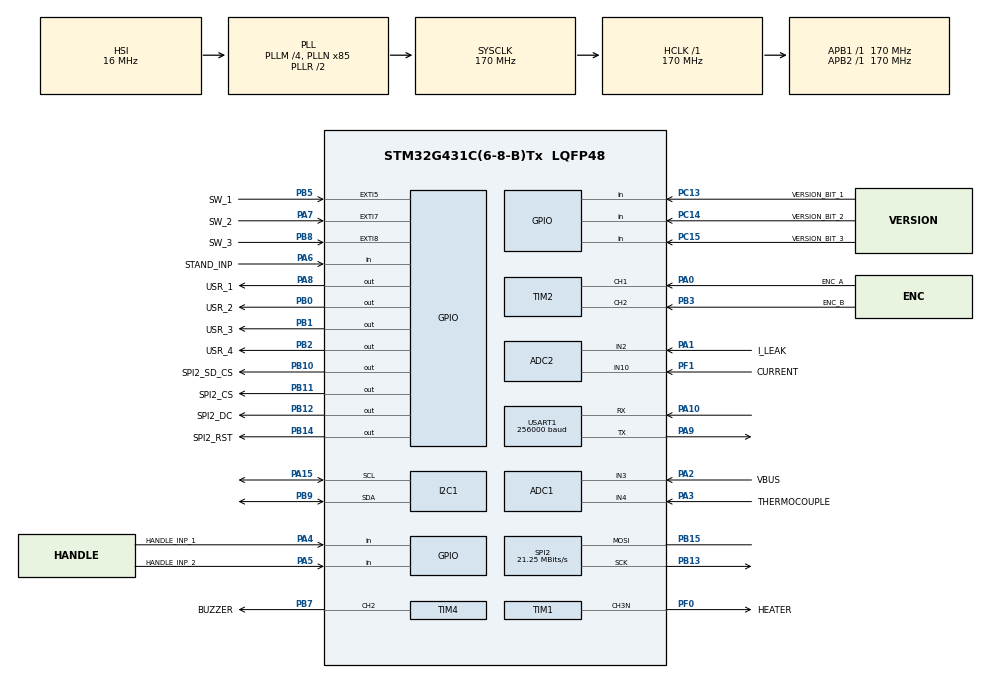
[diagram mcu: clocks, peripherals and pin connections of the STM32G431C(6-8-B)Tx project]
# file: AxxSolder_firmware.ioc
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ADC1.Channel-11\#ChannelRegularConversion=ADC_CHANNEL_3
ADC1.Channel-21\#ChannelRegularConversion=ADC_CHANNEL_4
ADC1.Channel-22\#ChannelRegularConversion=ADC_CHANNEL_TEMPSENSOR_ADC1
ADC1.ClockPrescaler=ADC_CLOCK_ASYNC_DIV4
ADC1.ContinuousConvMode=ENABLE
ADC1.DMAContinuousRequests=ENABLE
ADC1.DiscontinuousConvMode=DISABLE
ADC1.EnableAnalogWatchDog1=false
ADC1.EnableInjectedConversion=DISABLE
ADC1.EnableRegularConversion=ENABLE
ADC1.ExternalTrigConv=ADC_SOFTWARE_START
ADC1.ExternalTrigConvEdge=ADC_EXTERNALTRIGCONVEDGE_NONE
ADC1.NbrOfConversion=3
ADC1.NbrOfConversionFlag=1
ADC1.OffsetNumber-11\#ChannelRegularConversion=ADC_OFFSET_NONE
ADC1.OffsetNumber-21\#ChannelRegularConversion=ADC_OFFSET_NONE
ADC1.OffsetNumber-22\#ChannelRegularConversion=ADC_OFFSET_NONE
ADC1.Overrun=ADC_OVR_DATA_PRESERVED
ADC1.Rank-11\#ChannelRegularConversion=1
ADC1.Rank-21\#ChannelRegularConversion=2
ADC1.Rank-22\#ChannelRegularConversion=3
ADC1.SamplingTime-11\#ChannelRegularConversion=ADC_SAMPLETIME_247CYCLES_5
ADC1.SamplingTime-21\#ChannelRegularConversion=ADC_SAMPLETIME_247CYCLES_5
ADC1.SamplingTime-22\#ChannelRegularConversion=ADC_SAMPLETIME_247CYCLES_5
ADC1.master=1
ADC2.AWD1HighThreshold=2000
ADC2.AWD1ITMode=ENABLE
ADC2.Channel-4\#ChannelRegularConversion=ADC_CHANNEL_2
ADC2.Channel-5\#ChannelRegularConversion=ADC_CHANNEL_10
ADC2.ClockPrescaler=ADC_CLOCK_ASYNC_DIV4
ADC2.ContinuousConvMode=DISABLE
ADC2.DMAContinuousRequests=ENABLE
ADC2.EnableAnalogWatchDog1=true
ADC2.NbrOfConversion=2
ADC2.NbrOfConversionFlag=1
ADC2.OffsetNumber-4\#ChannelRegularConversion=ADC_OFFSET_NONE
ADC2.OffsetNumber-5\#ChannelRegularConversion=ADC_OFFSET_NONE
ADC2.Rank-4\#ChannelRegularConversion=1
ADC2.Rank-5\#ChannelRegularConversion=2
ADC2.SamplingTime-4\#ChannelRegularConversion=ADC_SAMPLETIME_2CYCLES_5
ADC2.SamplingTime-5\#ChannelRegularConversion=ADC_SAMPLETIME_2CYCLES_5
ADC2.WatchdogChannel=ADC_CHANNEL_2
Dma.ADC1.1.Direction=DMA_PERIPH_TO_MEMORY
Dma.ADC1.1.EventEnable=DISABLE
Dma.ADC1.1.Instance=DMA1_Channel3
Dma.ADC1.1.MemDataAlignment=DMA_MDATAALIGN_HALFWORD
Dma.ADC1.1.MemInc=DMA_MINC_ENABLE
Dma.ADC1.1.Mode=DMA_CIRCULAR
Dma.ADC1.1.PeriphDataAlignment=DMA_PDATAALIGN_HALFWORD
Dma.ADC1.1.PeriphInc=DMA_PINC_DISABLE
Dma.ADC1.1.Polarity=HAL_DMAMUX_REQ_GEN_RISING
Dma.ADC1.1.Priority=DMA_PRIORITY_LOW
Dma.ADC1.1.RequestNumber=1
Dma.ADC1.1.SignalID=NONE
Dma.ADC1.1.SyncEnable=DISABLE
Dma.ADC1.1.SyncPolarity=HAL_DMAMUX_SYNC_NO_EVENT
Dma.ADC1.1.SyncRequestNumber=1
Dma.ADC1.1.SyncSignalID=NONE
Dma.ADC2.3.Direction=DMA_PERIPH_TO_MEMORY
Dma.ADC2.3.EventEnable=DISABLE
Dma.ADC2.3.Instance=DMA1_Channel4
Dma.ADC2.3.MemDataAlignment=DMA_MDATAALIGN_HALFWORD
Dma.ADC2.3.MemInc=DMA_MINC_ENABLE
Dma.ADC2.3.Mode=DMA_NORMAL
Dma.ADC2.3.PeriphDataAlignment=DMA_PDATAALIGN_HALFWORD
Dma.ADC2.3.PeriphInc=DMA_PINC_DISABLE
Dma.ADC2.3.Polarity=HAL_DMAMUX_REQ_GEN_RISING
Dma.ADC2.3.Priority=DMA_PRIORITY_LOW
Dma.ADC2.3.RequestNumber=1
Dma.ADC2.3.SignalID=NONE
Dma.ADC2.3.SyncEnable=DISABLE
Dma.ADC2.3.SyncPolarity=HAL_DMAMUX_SYNC_NO_EVENT
Dma.ADC2.3.SyncRequestNumber=1
Dma.ADC2.3.SyncSignalID=NONE
Dma.Request0=SPI2_TX
Dma.Request1=ADC1
Dma.Request2=USART1_TX
Dma.Request3=ADC2
Dma.SPI2_TX.0.Direction=DMA_MEMORY_TO_PERIPH
Dma.SPI2_TX.0.EventEnable=DISABLE
Dma.SPI2_TX.0.Instance=DMA1_Channel1
Dma.SPI2_TX.0.MemDataAlignment=DMA_MDATAALIGN_BYTE
Dma.SPI2_TX.0.MemInc=DMA_MINC_ENABLE
Dma.SPI2_TX.0.Mode=DMA_NORMAL
Dma.SPI2_TX.0.PeriphDataAlignment=DMA_PDATAALIGN_BYTE
Dma.SPI2_TX.0.PeriphInc=DMA_PINC_DISABLE
Dma.SPI2_TX.0.Polarity=HAL_DMAMUX_REQ_GEN_RISING
Dma.SPI2_TX.0.Priority=DMA_PRIORITY_LOW
Dma.SPI2_TX.0.RequestNumber=1
Dma.SPI2_TX.0.SignalID=NONE
Dma.SPI2_TX.0.SyncEnable=DISABLE
Dma.SPI2_TX.0.SyncPolarity=HAL_DMAMUX_SYNC_NO_EVENT
Dma.SPI2_TX.0.SyncRequestNumber=1
Dma.SPI2_TX.0.SyncSignalID=NONE
Dma.USART1_TX.2.Direction=DMA_MEMORY_TO_PERIPH
Dma.USART1_TX.2.EventEnable=DISABLE
Dma.USART1_TX.2.Instance=DMA1_Channel2
Dma.USART1_TX.2.MemDataAlignment=DMA_MDATAALIGN_BYTE
Dma.USART1_TX.2.MemInc=DMA_MINC_ENABLE
Dma.USART1_TX.2.Mode=DMA_NORMAL
Dma.USART1_TX.2.PeriphDataAlignment=DMA_PDATAALIGN_BYTE
Dma.USART1_TX.2.PeriphInc=DMA_PINC_DISABLE
Dma.USART1_TX.2.Polarity=HAL_DMAMUX_REQ_GEN_RISING
Dma.USART1_TX.2.Priority=DMA_PRIORITY_LOW
Dma.USART1_TX.2.RequestNumber=1
Dma.USART1_TX.2.SignalID=NONE
Dma.USART1_TX.2.SyncEnable=DISABLE
Dma.USART1_TX.2.SyncPolarity=HAL_DMAMUX_SYNC_NO_EVENT
Dma.USART1_TX.2.SyncRequestNumber=1
Dma.USART1_TX.2.SyncSignalID=NONE
I2C1.Timing=0x40B285C2
Mcu.Family=STM32G4
Mcu.Name=STM32G431C(6-8-B)Tx
Mcu.Package=LQFP48
NVIC.ADC1_2_IRQn=true\:10\:0\:true\:false\:true\:true\:true\:true
NVIC.DMA1_Channel1_IRQn=true\:0\:0\:true\:false\:true\:false\:true\:true
NVIC.DMA1_Channel2_IRQn=true\:0\:0\:false\:false\:true\:false\:true\:true
NVIC.DMA1_Channel3_IRQn=true\:0\:0\:false\:false\:true\:false\:true\:true
NVIC.DMA1_Channel4_IRQn=true\:0\:0\:false\:false\:true\:false\:true\:true
NVIC.EXTI9_5_IRQn=true\:0\:0\:false\:false\:true\:true\:true\:true
NVIC.PriorityGroup=NVIC_PRIORITYGROUP_4
NVIC.TIM1_BRK_TIM15_IRQn=true\:0\:0\:false\:false\:true\:true\:true\:true
NVIC.TIM1_CC_IRQn=true\:0\:0\:false\:false\:true\:true\:true\:true
NVIC.TIM1_TRG_COM_TIM17_IRQn=true\:0\:0\:false\:false\:true\:true\:true\:true
NVIC.TIM1_UP_TIM16_IRQn=true\:0\:0\:false\:false\:true\:true\:true\:true
NVIC.TIM6_DAC_IRQn=true\:0\:0\:false\:false\:true\:true\:true\:true
NVIC.TIM7_IRQn=true\:0\:0\:false\:false\:true\:true\:true\:true
NVIC.USART1_IRQn=true\:0\:0\:false\:false\:true\:true\:true\:true
PA0.GPIO_Label=ENC_A
PA0.Signal=S_TIM2_CH1
PA1.GPIO_Label=I_LEAK
PA1.Mode=IN2-Single-Ended
PA1.Signal=ADC2_IN2
PA10.Mode=Asynchronous
PA10.Signal=USART1_RX
PA13.Mode=Serial_Wire
PA13.Signal=SYS_JTMS-SWDIO
PA14.Mode=Serial_Wire
PA14.Signal=SYS_JTCK-SWCLK
PA15.Mode=I2C
PA15.Signal=I2C1_SCL
PA2.GPIO_Label=VBUS
PA2.Mode=IN3-Single-Ended
PA2.Signal=ADC1_IN3
PA3.GPIO_Label=THERMOCOUPLE
PA3.Mode=IN4-Single-Ended
PA3.Signal=ADC1_IN4
PA4.GPIO_Label=HANDLE_INP_1
PA4.Signal=GPIO_Input
PA5.GPIO_Label=HANDLE_INP_2
PA5.Signal=GPIO_Input
PA6.GPIO_Label=STAND_INP
PA6.Signal=GPIO_Input
PA7.GPIO_Label=SW_2
PA7.Signal=GPXTI7
PA8.GPIO_Label=USR_1
PA8.Signal=GPIO_Output
PA9.Mode=Asynchronous
PA9.Signal=USART1_TX
PB0.GPIO_Label=USR_2
PB0.Signal=GPIO_Output
PB1.GPIO_Label=USR_3
PB1.Signal=GPIO_Output
PB10.GPIO_Label=SPI2_SD_CS
PB10.Signal=GPIO_Output
PB11.GPIO_Label=SPI2_CS
PB11.Signal=GPIO_Output
PB12.GPIO_Label=SPI2_DC
PB12.Signal=GPIO_Output
PB13.Mode=Simplex_Bidirectional_Master
PB13.Signal=SPI2_SCK
PB14.GPIO_Label=SPI2_RST
PB14.Signal=GPIO_Output
PB15.Mode=Simplex_Bidirectional_Master
PB15.Signal=SPI2_MOSI
PB2.GPIO_Label=USR_4
PB2.Signal=GPIO_Output
PB3.GPIO_Label=ENC_B
PB3.Signal=S_TIM2_CH2
PB5.GPIO_Label=SW_1
PB5.Signal=GPXTI5
PB7.GPIO_Label=BUZZER
PB7.Signal=S_TIM4_CH2
PB8-BOOT0.GPIO_Label=SW_3
PB8-BOOT0.Signal=GPXTI8
PB9.Mode=I2C
PB9.Signal=I2C1_SDA
PC13.GPIO_Label=VERSION_BIT_1
PC13.Signal=GPIO_Input
PC14-OSC32_IN.GPIO_Label=VERSION_BIT_2
PC14-OSC32_IN.Signal=GPIO_Input
PC15-OSC32_OUT.GPIO_Label=VERSION_BIT_3
PC15-OSC32_OUT.Signal=GPIO_Input
PF0-OSC_IN.GPIO_Label=HEATER
PF0-OSC_IN.Mode=PWM Generation3 CH3N
PF0-OSC_IN.Signal=TIM1_CH3N
PF1-OSC_OUT.GPIO_Label=CURRENT
PF1-OSC_OUT.Mode=IN10-Single-Ended
PF1-OSC_OUT.Signal=ADC2_IN10
ProjectManager.HeapSize=0x200
ProjectManager.StackSize=0x400
ProjectManager.TargetToolchain=STM32CubeIDE
RCC.ADC12Freq_Value=170000000
RCC.AHBFreq_Value=170000000
RCC.APB1Freq_Value=170000000
RCC.APB1TimFreq_Value=170000000
RCC.APB2Freq_Value=170000000
RCC.APB2TimFreq_Value=170000000
RCC.CK48CLockSelection=RCC_USBCLKSOURCE_HSI48
RCC.CortexFreq_Value=170000000
RCC.EXTERNAL_CLOCK_VALUE=12288000
RCC.HCLKFreq_Value=170000000
RCC.HSE_VALUE=8000000
RCC.HSI48_VALUE=48000000
RCC.HSI_VALUE=16000000
RCC.LSE_VALUE=32768
RCC.PLLM=RCC_PLLM_DIV4
RCC.PLLN=85
RCC.SYSCLKFreq_VALUE=170000000
RCC.SYSCLKSource=RCC_SYSCLKSOURCE_PLLCLK
RCC.USBFreq_Value=48000000
RCC.VCOOutputFreq_Value=340000000
SH.S_TIM2_CH1.0=TIM2_CH1,Encoder_Interface
SH.S_TIM2_CH2.0=TIM2_CH2,Encoder_Interface
SH.S_TIM4_CH2.0=TIM4_CH2,PWM Generation2 CH2
SPI2.BaudRatePrescaler=SPI_BAUDRATEPRESCALER_8
SPI2.CLKPolarity=SPI_POLARITY_LOW
SPI2.CalculateBaudRate=21.25 MBits/s
SPI2.DataSize=SPI_DATASIZE_8BIT
SPI2.Direction=SPI_DIRECTION_1LINE
SPI2.Mode=SPI_MODE_MASTER
SPI2.VirtualType=VM_MASTER
TIM1.AutoReloadPreload=TIM_AUTORELOAD_PRELOAD_ENABLE
TIM1.Channel-PWM\ Generation1\ No\ Output=TIM_CHANNEL_1
TIM1.Channel-PWM\ Generation3\ CH3N=TIM_CHANNEL_3
TIM1.PeriodNoDither=500
TIM1.Prescaler=17-1
TIM1.TIM_MasterOutputTrigger=TIM_TRGO_RESET
TIM16.AutoReloadPreload=TIM_AUTORELOAD_PRELOAD_ENABLE
TIM16.PeriodNoDither=500-1
TIM16.Prescaler=17000-1
TIM17.AutoReloadPreload=TIM_AUTORELOAD_PRELOAD_ENABLE
TIM17.PeriodNoDither=50-1
TIM17.Prescaler=17000
TIM2.EncoderMode=TIM_ENCODERMODE_TI12
TIM2.IC1Polarity=TIM_ICPOLARITY_FALLING
TIM4.AutoReloadPreload=TIM_AUTORELOAD_PRELOAD_ENABLE
TIM4.Channel-PWM\ Generation2\ CH2=TIM_CHANNEL_2
TIM4.PeriodNoDither=100
TIM4.Prescaler=1700-1
TIM4.PulseNoDither_2=0
TIM6.AutoReloadPreload=TIM_AUTORELOAD_PRELOAD_ENABLE
TIM6.PeriodNoDither=250
TIM6.Prescaler=17000-1
TIM7.AutoReloadPreload=TIM_AUTORELOAD_PRELOAD_ENABLE
TIM7.PeriodNoDither=10-1
TIM7.Prescaler=8500-1
TIM7.TIM_MasterOutputTrigger=TIM_TRGO_UPDATE
USART1.BaudRate=256000
USART1.VirtualMode-Asynchronous=VM_ASYNC
VP_ADC1_TempSens_Input.Mode=IN-TempSens
VP_CRC_VS_CRC.Mode=CRC_Activate
VP_SYS_VS_DBSignals.Mode=DisableDeadBatterySignals
VP_TIM16_VS_ClockSourceINT.Mode=Enable_Timer
VP_TIM17_VS_ClockSourceINT.Mode=Enable_Timer
VP_TIM17_VS_OPM.Mode=OPM_bit
VP_TIM1_VS_no_output1.Mode=PWM Generation1 No Output
VP_TIM6_VS_ClockSourceINT.Mode=Enable_Timer
VP_TIM7_VS_ClockSourceINT.Mode=Enable_Timer
VP_TIM7_VS_OPM.Mode=OPM_bit
VP_TIM8_VS_OPM.Mode=OPM_bit
board=custom

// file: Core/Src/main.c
/* USER CODE BEGIN Header */
/**
  ******************************************************************************
  * @file           : main.c
  * @author  		: Axel Johansson, Stockholm, Sweden
  * @brief          : Main program body of AxxSodler
  ******************************************************************************
  * @attention
  *
  * Copyright (c) 2024 STMicroelectronics.
  * All rights reserved.
  *
  * This software is licensed under terms that can be found in the LICENSE file
  * in the root directory of this software component.
  * If no LICENSE file comes with this software, it is provided AS-IS.
  *
  ******************************************************************************
  */
/* USER CODE END Header */
#include "main.h"

/* USER CODE BEGIN Includes */
#include "lcd.h"
#include "string.h"
#include "pid.h"
#include "moving_average.h"
#include "hysteresis.h"
#include "type_packers.h"
#include "flash.h"
#include "stusb4500.h"
#include "buzzer.h"
#include "debug.h"
#include "menu_settings.h"
#include <math.h>
#include <stdio.h>
#include <float.h>

//#include "usbd_cdc_if.h"
/* USER CODE END Includes */

/* USER CODE BEGIN PTD */
uint8_t fw_version_major =  3;
uint8_t fw_version_minor =  5;
uint8_t fw_version_patch =  2;

//#define PID_TUNING
DEBUG_VERBOSITY_t debugLevel = DEBUG_INFO;

/* Cartridge type specific PID parameters */
#define KP_NT115 					5
#define KI_NT115 					2
#define KD_NT115 					0.3
#define MAX_I_NT115 				300

#define KP_T210 					7
#define KI_T210 					4
#define KD_T210 					0.3
#define MAX_I_T210 					300

#define KP_T245 					8
#define KI_T245 					2
#define KD_T245 					0.5
#define MAX_I_T245 					300

/* General PID parameters */
#define PID_MAX_OUTPUT 500.0f
#define FIXED_MEASURE_DUTY (PID_MAX_OUTPUT / 2)
#define PID_UPDATE_INTERVAL 25
#define PID_ADD_I_MIN_ERROR 75
float PID_NEG_ERROR_I_MULT = 7;
float PID_NEG_ERROR_I_BIAS = 1;

/* Timing constants */
uint32_t previous_millis_display = 0;
uint32_t interval_display = 40;

uint32_t previous_millis_debug = 0;
uint32_t interval_debug = 50;

uint32_t previous_millis_heating_halted_update = 0;
uint32_t interval_heating_halted_update = 500;

uint32_t previous_millis_left_stand = 0;

uint32_t previous_millis_standby = 0;

uint32_t previous_measure_current_update = 0;
uint32_t interval_measure_current = 250;

uint32_t previous_sensor_update_high_update = 0;
uint32_t interval_sensor_update_high_update = 10;

uint32_t previous_sensor_update_low_update = 0;
uint32_t interval_sensor_update_low_update = 100;

uint32_t previous_millis_popup = 0;
uint32_t interval_popup = 2000;

uint32_t previous_stand_debounce = 0;
uint32_t interval_stand_debounce = 100;

cartridge_state_t cartridge_state = ATTACHED;
cartridge_state_t previous_cartridge_state = ATTACHED;

/* power sources */
power_source_t power_source = POWER_DC;

uint8_t sleep_state_written_to_LCD = 0;
uint8_t standby_state_written_to_LCD = 0;

/* Custom tuning parameters */
float Kp_tuning = 0;
float Ki_tuning = 0;
float Kd_tuning = 0;
float temperature_tuning = 100;
float PID_MAX_I_LIMIT_tuning = 0;

/* Allow use of custom temperatue, used for tuning */
uint8_t custom_temperature_on = 0;

/* Buffer for UART print */
char UART_buffer[40];

/* Buffer for UART print */
char DISPLAY_buffer[40];

/* ADC Buffer */
#define ADC1_BUF_LEN 57 //3*19
uint16_t ADC1_BUF[ADC1_BUF_LEN];

/* RAW ADC from current measurement */
uint16_t adc2_dma_buffer[2]; // [0] = channel 2, [1] = channel 10
uint16_t current_raw = 0;
uint16_t current_leak = 0;

/* Stand toggle variables */
uint8_t previous_stand_status = 0;
uint8_t stand_debounced_flag = 0;

/* Thermocouple temperature */
float TC_temp = 0;

/* Flag to indicate that startup sequence is done */
uint8_t startup_done = 0;

/* Flag to indicate that settings menu is active */
uint8_t settings_menu_active = 0;

/* Flag to indicate if beep has been done at set temperature */
uint8_t beeped_at_set_temp = 0;

/* Flag to indicate if a popup is shown */
uint8_t popup_shown = 0;

/* Variables for thermocouple outlier detection */
float TC_temp_from_ADC = 0;
float TC_temp_from_ADC_previous = 0;
float TC_temp_from_ADC_diff = 0;
uint16_t TC_outliers_detected = 0;
#define TC_OUTLIERS_THRESHOLD 300

/* Max allowed tip temperature */
#define EMERGENCY_SHUTDOWN_TEMPERATURE 490

/* Constants for scaling input voltage ADC value*/
#define VOLTAGE_COMPENSATION 0.00840442388
#define CURRENT_COMPENSATION 0.002864

/* Constants for scaling power in W to correct duty cycle */
#define POWER_CONVERSION_FACTOR 0.123

/* Min allowed bus voltage and power */
#define MIN_BUSVOLTAGE 8.0
#define MIN_BUSPOWER 8.0
#define USB_PD_POWER_REDUCTION_FACTOR 1.0

/* Max allowed power per handle type */
#define NT115_MAX_POWER 22
#define T210_MAX_POWER 	65
#define T245_MAX_POWER 	130

/* TC Compensation constants */
#define TC_COMPENSATION_X2_NT115 (5.1026665462522864e-05)
#define TC_COMPENSATION_X1_NT115 0.42050803230712813
#define TC_COMPENSATION_X0_NT115 20.14538589052425

#define TC_COMPENSATION_X2_T210 (4.223931712905644e-06)
#define TC_COMPENSATION_X1_T210 0.31863796444354214
#define TC_COMPENSATION_X0_T210 20.968033870812942

#define TC_COMPENSATION_X2_T245 (-4.735112838956741e-07)
#define TC_COMPENSATION_X1_T245 0.11936452029674384
#define TC_COMPENSATION_X0_T245 23.777399955382318

/* Constants for internal MCU temperture */
#define V30 		0.76 			// from datasheet
#define VSENSE 		(3.3/4096.0) 	// VSENSE value
#define Avg_Slope 	0.0025 			// 2.5mV from datasheet

/* Largest delta temperature before detecting a faulty or missing cartridge */
#define MAX_TC_DELTA_FAULTDETECTION 50

/* Define time for long button press */
#define BTN_LONG_PRESS 15 //*50ms (htim16 interval) --> 15 = 750ms
#define BTN_LONG_LONG_PRESS 40 //*50ms (htim16 interval) --> 40 = 2000ms

/* Button flags */
volatile uint8_t SW_ready = 1;
volatile uint8_t SW_1_pressed = 0;
volatile uint8_t SW_2_pressed = 0;
volatile uint8_t SW_3_pressed = 0;
volatile uint8_t SW_1_pressed_long = 0;
volatile uint8_t SW_1_pressed_long_long = 0;
volatile uint8_t SW_2_pressed_long = 0;
volatile uint8_t SW_3_pressed_long = 0;

/* UART send buffers */
#define MAX_BUFFER_LEN 250
uint8_t UART_transmit_buffer[MAX_BUFFER_LEN];
uint8_t UART_packet_index = 0;
uint8_t UART_packet_length = 0;

///////////////////////////POWER GRAPH
uint8_t draw_pwr_graph=0;

// Display of temperature and power graph

#define background RGB_to_BRG(C_BLACK)
#define color_actual RGB_to_BRG(C_WHITE)

#define GRAPH_X0  34
#define GRAPH_Y0  217
#define GRAPH_WIDTH  250
#define GRAPH_HEIGHT 130

#define TEMP_MIN 0
#define TEMP_MAX 450
#define POWER_MIN 0
#define POWER_MAX 100

#define GRAPH_POINTS 100

#define GRAPH_Color_TEMP    C_FIREBRICK        // Temperature graph color
#define GRAPH_Color_POWER   C_LAWN_GREEN   // Power graph color

#define DASH_LEN_COLOR   C_DARK_GRAY   // Coordinate grid dashed line color
#define DASH_LEN 5                     // Dash length in pixels
#define GAP_LEN  5                     // Gap length in pixels
#define THICKNESS_LEN  1               // Line thickness in pixels

uint16_t temp_array[GRAPH_POINTS];
uint16_t power_array[GRAPH_POINTS];
uint16_t prev_temp_array[GRAPH_POINTS];
uint16_t prev_power_array[GRAPH_POINTS];
uint8_t index_graph = 0;

static uint8_t initialized = 0;

// Structure for storing a line with its color
typedef struct {
    int x1, y1, x2, y2;
    uint16_t color;  // B_RED or B_BLUE or others
} Line;

void add_data_point(uint16_t temp, uint16_t power) {
    temp_array[index_graph] = temp;
    power_array[index_graph] = power;
    index_graph++;
    if (index_graph >= GRAPH_POINTS) index_graph = 0; // Circular buffer
}

static Line temp_lines_prev[GRAPH_POINTS - 1] = {0};
static Line power_lines_prev[GRAPH_POINTS - 1] = {0};

// Universal dashed line using UG_FillFrame()
// dash_len  – dash length in pixels
// gap_len   – gap length in pixels
// thickness – line thickness in pixels
void draw_dashed_line_fillframe(int x1, int y1, int x2, int y2, uint16_t color,
                                uint8_t dash_len, uint8_t gap_len, uint8_t thickness) {
    int dx = abs(x2 - x1), sx = x1 < x2 ? 1 : -1;
    int dy = -abs(y2 - y1), sy = y1 < y2 ? 1 : -1;
    int err = dx + dy, e2;

    uint8_t phase = 0;          // Position inside dash or gap
    uint8_t draw = 1;           // Draw or skip
    uint8_t segment_len = dash_len;

    while (1) {
        if (draw) {
            UG_FillFrame(x1, y1, x1 + (thickness - 1), y1 + (thickness - 1), color);
        }
        phase++;
        if (phase >= segment_len) {
            phase = 0;
            draw = !draw; // Switch drawing mode
            segment_len = draw ? dash_len : gap_len;
        }

        if (x1 == x2 && y1 == y2) break;
        e2 = 2 * err;
        if (e2 >= dy) { err += dy; x1 += sx; }
        if (e2 <= dx) { err += dx; y1 += sy; }
    }
}

void draw_graph_init(void) {
    // Background, grid, and labels are drawn once
    UG_FillFrame(GRAPH_X0, GRAPH_Y0 - GRAPH_HEIGHT , GRAPH_X0 + GRAPH_WIDTH, GRAPH_Y0, background);

    // Draw horizontal dashed lines
    for (int y = 0; y <= GRAPH_HEIGHT; y += GRAPH_HEIGHT / 5) {
        draw_dashed_line_fillframe(GRAPH_X0, GRAPH_Y0 - y, GRAPH_X0 + GRAPH_WIDTH, GRAPH_Y0 - y,
        		DASH_LEN_COLOR, DASH_LEN, GAP_LEN, THICKNESS_LEN); // dash=1, gap=5, thickness=1
    }

    // Draw vertical dashed lines
    for (int x = 0; x <= GRAPH_WIDTH; x += GRAPH_WIDTH / 5) {
        draw_dashed_line_fillframe(GRAPH_X0 + x, GRAPH_Y0 - GRAPH_HEIGHT, GRAPH_X0 + x, GRAPH_Y0,
        		DASH_LEN_COLOR, DASH_LEN, GAP_LEN, THICKNESS_LEN);
    }

    // Labels along the time axis (X, in seconds)
    float step_time_sec = ((float)GRAPH_WIDTH / 5.0f) * ((float)interval_display / 1000.0f);

    for (int i = 0; i <= 5; i++) {
        int x_pos = GRAPH_X0 + i * (GRAPH_WIDTH / 5);
        char buf[12];

        if (i == 0) {
            snprintf(buf, sizeof(buf), "0 s");
        } else {
            // Format time without decimals
            snprintf(buf, sizeof(buf), "%.0f", i * step_time_sec);
        }

        int y_pos = GRAPH_Y0 + 2;

        // For the last label, shift 10 pixels to the left
        int x_draw = (i == 5) ? (x_pos - 15) : x_pos;

        LCD_PutStr(x_draw, y_pos, buf, FONT_arial_19X22, C_PALE_GREEN, background);
    }

    initialized = 1;
}

// Universal function for a line with a given thickness
void draw_line_with_thickness(int x1, int y1, int x2, int y2, uint16_t color, uint8_t thickness) {
    int dx = abs(x2 - x1), sx = x1 < x2 ? 1 : -1;
    int dy = -abs(y2 - y1), sy = y1 < y2 ? 1 : -1;
    int err = dx + dy, e2;

    while (1) {
        // Thickness in pixels (square brush)
        UG_FillFrame(x1, y1, x1 + (thickness - 1), y1 + (thickness - 1), color);

        if (x1 == x2 && y1 == y2) break;
        e2 = 2 * err;
        if (e2 >= dy) { err += dy; x1 += sx; }
        if (e2 <= dx) { err += dx; y1 += sy; }
    }
}

// Restore grid dash
void restore_grid_point(int x, int y) {
    // Horizontal grid lines
    for (int gy = 0; gy <= GRAPH_HEIGHT; gy += GRAPH_HEIGHT / 5) {
        int grid_y = GRAPH_Y0 - gy;
        if (abs(y - grid_y) <= THICKNESS_LEN) {
            int cycle_len = DASH_LEN + GAP_LEN;
            int dash_index = (x - GRAPH_X0) / cycle_len;
            int dash_start = GRAPH_X0 + dash_index * cycle_len;
            int dash_end = dash_start + DASH_LEN - 1;

            if (dash_end > GRAPH_X0 + GRAPH_WIDTH) dash_end = GRAPH_X0 + GRAPH_WIDTH;

            // Draw the whole dash
            UG_FillFrame(dash_start, grid_y,
                         dash_end,   grid_y,
						 DASH_LEN_COLOR);
            return;
        }
    }

    // Vertical grid lines
    for (int gx = 0; gx <= GRAPH_WIDTH; gx += GRAPH_WIDTH / 5) {
        int grid_x = GRAPH_X0 + gx;
        if (abs(x - grid_x) <= THICKNESS_LEN) {
            int cycle_len = DASH_LEN + GAP_LEN;
            int dash_index = (GRAPH_Y0 - y) / cycle_len;
            int dash_start = GRAPH_Y0 - dash_index * cycle_len;
            int dash_end = dash_start - (DASH_LEN - 1);

            if (dash_end < GRAPH_Y0 - GRAPH_HEIGHT) dash_end = GRAPH_Y0 - GRAPH_HEIGHT;

            UG_FillFrame(grid_x,
                         dash_end, grid_x,
                         dash_start,
						 DASH_LEN_COLOR);
            return;
        }
    }
}

// Erases a line 2 pixels thick and restores the grid
void erase_line_and_restore_grid(int x1, int y1, int x2, int y2) {
    // Erase with thickness of 2 pixels
    draw_line_with_thickness(x1, y1, x2, y2, background, 2);

    int dx = abs(x2 - x1);
    int dy = abs(y2 - y1);

    int sx = (x1 < x2) ? 1 : -1;
    int sy = (y1 < y2) ? 1 : -1;

    int err = dx - dy;

    while (1) {
        restore_grid_point(x1, y1);

        if (x1 == x2 && y1 == y2)
            break;

        int e2 = err * 2;
        if (e2 > -dy) {
            err -= dy;
            x1 += sx;
        }
        if (e2 < dx) {
            err += dx;
            y1 += sy;
        }
    }
}

// Check if two line segments overlap within rectangles, with margin (thickness)
bool lines_overlap(Line *l1, Line *l2, int thickness) {
    int l1_xmin = l1->x1 < l1->x2 ? l1->x1 : l1->x2;
    int l1_xmax = l1->x1 > l1->x2 ? l1->x1 : l1->x2;
    int l1_ymin = l1->y1 < l1->y2 ? l1->y1 : l1->y2;
    int l1_ymax = l1->y1 > l1->y2 ? l1->y1 : l1->y2;

    int l2_xmin = l2->x1 < l2->x2 ? l2->x1 : l2->x2;
    int l2_xmax = l2->x1 > l2->x2 ? l2->x1 : l2->x2;
    int l2_ymin = l2->y1 < l2->y2 ? l2->y1 : l2->y2;
    int l2_ymax = l2->y1 > l2->y2 ? l2->y1 : l2->y2;

    // Add thickness margin for "overlap"
    l1_xmin -= thickness;
    l1_xmax += thickness;
    l1_ymin -= thickness;
    l1_ymax += thickness;

    l2_xmin -= thickness;
    l2_xmax += thickness;
    l2_ymin -= thickness;
    l2_ymax += thickness;

    bool x_overlap = (l1_xmin <= l2_xmax) && (l1_xmax >= l2_xmin);
    bool y_overlap = (l1_ymin <= l2_ymax) && (l1_ymax >= l2_ymin);

    return x_overlap && y_overlap;
}

// Helper function for drawing an axis with labels
// values      - array of values for labels
// count       - number of labels in the array
// x           - horizontal position for label output
// is_left_axis - true if the axis is on the left (labels on the left), false if on the right
// unit_start  - suffix for the first label (e.g., "°C" or "%"), can be NULL
// unit_end    - suffix for the last label, can be NULL
void draw_axis(const int *values, int count, int x, bool is_left_axis,
               uint16_t color, const char *unit_start, const char *unit_end) {
    // Upper and lower Y boundaries so labels don't go outside the grid
    int y_min = GRAPH_Y0 - GRAPH_HEIGHT + 10; // slightly below the top grid line
    int y_max = GRAPH_Y0 - 5;                 // slightly above the bottom grid line

    for (int i = 0; i < count; i++) {
        int y_pos;

        if (i == 0) {
            y_pos = y_max;  // Bottom label (minimum value)
        } else if (i == count - 1) {
            y_pos = y_min;  // Top label (maximum value)
        } else {
            // Evenly distribute remaining labels between top and bottom boundaries
            float fraction = (float)i / (count - 1);
            y_pos = y_max - (int)((y_max - y_min) * fraction);
        }

        char buf[12];

        // Form a string with units only for the first label, others without units
        if (i == 0 && unit_start) {
            snprintf(buf, sizeof(buf), "%d%s", values[i], unit_start);
        } else {
            snprintf(buf, sizeof(buf), "%d", values[i]);
        }

        // For the left axis, use a fixed offset from the left (2 pixels)
        int x_pos = x;
        if (is_left_axis) {
            x_pos = 2;
        }

        // Output label on the screen with vertical offset -15 for visual alignment
        LCD_PutStr(x_pos, y_pos - 15, buf, FONT_arial_19X22, color, background);
    }
}

// Change graph axis label colors depending on sensor_values.current_state
void draw_axis_labels(void) {
    // Select label colors once depending on the state
    uint16_t color_temp_label = (sensor_values.current_state == RUN) ? color_actual : GRAPH_Color_TEMP;
    uint16_t color_power_label = (sensor_values.current_state == RUN) ? GRAPH_Color_POWER : C_BLUE;

    // Arrays of values for the temperature axis and the power axis
    int temp_values[] = {0, 90, 180, 270, 360, 450};
    int power_values[] = {0, 20, 40, 60, 80, 100};

    // Draw the left temperature axis (with "°C" symbol at the minimum value)
    draw_axis(temp_values, sizeof(temp_values)/sizeof(temp_values[0]), 2, true, color_temp_label, "°C", NULL);

    // Draw the right power axis (with % at the minimum value)
    draw_axis(power_values, sizeof(power_values)/sizeof(power_values[0]), GRAPH_X0 + GRAPH_WIDTH + 3, false, color_power_label, "%", "");
}

void check_and_update_labels(void) {
	uint8_t last_sensor_state = 0xFF;
	if (last_sensor_state != sensor_values.current_state) {
        draw_axis_labels();
        last_sensor_state = sensor_values.current_state;
    }
}

void draw_graph_update(void) {
    if (!initialized) {
        draw_graph_init();
    }

    check_and_update_labels();

    // Update temperature and power lines with partial erasing
    for (uint8_t i = 1; i < GRAPH_POINTS; i++) {
        uint8_t idx_prev = (index_graph + i - 1) % GRAPH_POINTS;
        uint8_t idx_curr = (index_graph + i) % GRAPH_POINTS;

        // Temperature points
        int x_prev_temp = GRAPH_X0 + ((i - 1) * GRAPH_WIDTH) / (GRAPH_POINTS - 1);
        int x_curr_temp = GRAPH_X0 + (i * GRAPH_WIDTH) / (GRAPH_POINTS - 1);
        int y_prev_temp = GRAPH_Y0 - ((temp_array[idx_prev] - TEMP_MIN) * GRAPH_HEIGHT) / (TEMP_MAX - TEMP_MIN);
        int y_curr_temp = GRAPH_Y0 - ((temp_array[idx_curr] - TEMP_MIN) * GRAPH_HEIGHT) / (TEMP_MAX - TEMP_MIN);

        uint16_t color_temp = (sensor_values.current_state == RUN) ? color_actual : GRAPH_Color_TEMP;

        Line new_temp_line = {x_prev_temp, y_prev_temp, x_curr_temp, y_curr_temp, color_temp};
        Line *old_temp_line = &temp_lines_prev[i - 1];

        // Power lines (offset +2 pixels)
        int x_prev_power = x_prev_temp;
        int x_curr_power = x_curr_temp;
        int y_prev_power = (GRAPH_Y0 - ((power_array[idx_prev] - POWER_MIN) * GRAPH_HEIGHT) / (POWER_MAX - POWER_MIN));
        int y_curr_power = (GRAPH_Y0 - ((power_array[idx_curr] - POWER_MIN) * GRAPH_HEIGHT) / (POWER_MAX - POWER_MIN));

        uint16_t color_power = (sensor_values.current_state == RUN) ? GRAPH_Color_POWER : C_BLUE;

        Line new_power_line = {x_prev_power, y_prev_power, x_curr_power, y_curr_power, color_power};
        Line *old_power_line = &power_lines_prev[i - 1];

        bool temp_line_changed = (old_temp_line->x1 != new_temp_line.x1) || (old_temp_line->y1 != new_temp_line.y1) ||
                                 (old_temp_line->x2 != new_temp_line.x2) || (old_temp_line->y2 != new_temp_line.y2) ||
                                 (old_temp_line->color != new_temp_line.color);

        bool power_line_changed = (old_power_line->x1 != new_power_line.x1) || (old_power_line->y1 != new_power_line.y1) ||
                                  (old_power_line->x2 != new_power_line.x2) || (old_power_line->y2 != new_power_line.y2) ||
                                  (old_power_line->color != new_power_line.color);

        // Check intersection of old lines if at least one line has changed
        if (temp_line_changed || power_line_changed) {
            bool overlap = false;

            if ((old_temp_line->x1 || old_temp_line->y1 || old_temp_line->x2 || old_temp_line->y2) &&
                (old_power_line->x1 || old_power_line->y1 || old_power_line->x2 || old_power_line->y2)) {
                overlap = lines_overlap(old_temp_line, old_power_line, 2);
            }

            if (overlap) {
                // Erase both lines and restore the grid
                erase_line_and_restore_grid(old_temp_line->x1, old_temp_line->y1, old_temp_line->x2, old_temp_line->y2);
                erase_line_and_restore_grid(old_power_line->x1, old_power_line->y1, old_power_line->x2, old_power_line->y2);
            } else {
                // Erase only changed lines individually
                if (temp_line_changed && (old_temp_line->x1 || old_temp_line->y1 || old_temp_line->x2 || old_temp_line->y2)) {
                    erase_line_and_restore_grid(old_temp_line->x1, old_temp_line->y1, old_temp_line->x2, old_temp_line->y2);
                }
                if (power_line_changed && (old_power_line->x1 || old_power_line->y1 || old_power_line->x2 || old_power_line->y2)) {
                    erase_line_and_restore_grid(old_power_line->x1, old_power_line->y1, old_power_line->x2, old_power_line->y2);
                }
            }
        }

        // Draw new lines
        draw_line_with_thickness(new_temp_line.x1, new_temp_line.y1, new_temp_line.x2, new_temp_line.y2, new_temp_line.color, 2);
        draw_line_with_thickness(new_power_line.x1, new_power_line.y1, new_power_line.x2, new_power_line.y2, new_power_line.color, 2);

        // Save new lines to prev
        temp_lines_prev[i - 1] = new_temp_line;
        power_lines_prev[i - 1] = new_power_line;
    }
}

///////////////////////////

enum handles attached_handle;

/* Struct to hold sensor values */
struct sensor_values_struct {
	float set_temperature;
	float thermocouple_temperature;
	float thermocouple_temperature_previous;
	float thermocouple_temperature_filtered;
	float requested_power;
	float requested_power_filtered;
	float bus_voltage;
	float heater_current;
	uint16_t leak_current;
	float mcu_temperature;
	float in_stand;
	float handle1_sense;
	float handle2_sense;
	mainstates current_state;
	mainstates previous_state;
	float max_power_watt;
	float USB_PD_power_limit;
};

/* Struct to hold sensor values */
sensor_values_struct sensor_values = {
    .set_temperature = 0.0f,
    .thermocouple_temperature = 0.0f,
    .thermocouple_temperature_previous = 0.0f,
    .thermocouple_temperature_filtered = 0.0f,
    .requested_power = 0.0f,
    .requested_power_filtered = 0.0f,
    .bus_voltage = 0.0f,
    .heater_current = 0.0f,
    .leak_current = 0,
    .mcu_temperature = 0.0f,
    .in_stand = 0.0f,
    .handle1_sense = 0.0f,
    .handle2_sense = 0.0f,
    .current_state = SLEEP,
    .previous_state = SLEEP,
    .max_power_watt = 0.0f,
    .USB_PD_power_limit = DBL_MAX
};

/* Struct to hold flash values */
Flash_values flash_values;
Flash_values default_flash_values = {.startup_temperature = 330,
									.temperature_offset = 0,
									.standby_temp = 150,
									.standby_time = 10,
									.emergency_time = 30,
									.buzzer_enabled = 1,
									.preset_temp_1 = 330,
									.preset_temp_2 = 430,
									.GPIO4_ON_at_run = 0,
									.screen_rotation = 0,
									.power_limit = 0,
									.current_measurement = 1,
									.startup_beep = 1,
									.deg_celsius = 1,
									.temp_cal_100 = 100,
									.temp_cal_200 = 200,
									.temp_cal_300 = 300,
									.temp_cal_350 = 350,
									.temp_cal_400 = 400,
									.temp_cal_450 = 450,
									.serial_debug_print = 0,
									.displayed_temp_filter = 5,
									.startup_temp_is_previous_temp = 0,
									.three_button_mode = 0,
									.beep_at_set_temp = 1,
									.beep_tone = 0,
									.momentary_stand = 0,
									.power_unit = 0,
									.detect_nt115 = 0};

/* PID data */
float PID_setpoint = 0.0f;

/* Flags for temp and current measurements */
volatile uint8_t current_measurement_requested = 0;
uint8_t current_measurement_done = 1;
uint8_t thermocouple_measurement_requested = 0;
uint8_t thermocouple_measurement_done = 1;

/* Moving average filters for sensor data */
FilterTypeDef thermocouple_temperature_filter_struct;
FilterTypeDef thermocouple_temperature_filtered_filter_struct;
FilterTypeDef requested_power_filtered_filter_struct;
FilterTypeDef mcu_temperature_filter_struct;
FilterTypeDef input_voltage_filterStruct;
FilterTypeDef current_filterStruct;
FilterTypeDef stand_sense_filterStruct;
FilterTypeDef handle1_sense_filterStruct;
FilterTypeDef handle2_sense_filterStruct;

/* Hysteresis filters for sensor data */
Hysteresis_FilterTypeDef thermocouple_temperature_filtered_hysteresis;

/* USER CODE END PTD */

ADC_HandleTypeDef hadc1;
ADC_HandleTypeDef hadc2;
DMA_HandleTypeDef hdma_adc1;
DMA_HandleTypeDef hdma_adc2;

CRC_HandleTypeDef hcrc;

I2C_HandleTypeDef hi2c1;

SPI_HandleTypeDef hspi2;
DMA_HandleTypeDef hdma_spi2_tx;

TIM_HandleTypeDef htim1;
TIM_HandleTypeDef htim2;
TIM_HandleTypeDef htim4;
TIM_HandleTypeDef htim6;
TIM_HandleTypeDef htim7;
TIM_HandleTypeDef htim8;
TIM_HandleTypeDef htim16;
TIM_HandleTypeDef htim17;

UART_HandleTypeDef huart1;
DMA_HandleTypeDef hdma_usart1_tx;

void SystemClock_Config(void);
static void MX_GPIO_Init(void);
static void MX_DMA_Init(void);
static void MX_ADC1_Init(void);
static void MX_ADC2_Init(void);
static void MX_CRC_Init(void);
static void MX_TIM1_Init(void);
static void MX_TIM2_Init(void);
static void MX_TIM4_Init(void);
static void MX_SPI2_Init(void);
static void MX_I2C1_Init(void);
static void MX_USART1_UART_Init(void);
static void MX_TIM7_Init(void);
static void MX_TIM8_Init(void);
static void MX_TIM6_Init(void);
static void MX_TIM16_Init(void);
static void MX_TIM17_Init(void);

/* USER CODE BEGIN 0 */
PID_TypeDef TPID;

/* Function to clamp d between the limits min and max */
float clamp(float d, float min, float max) {
    if (d < min) return min;
    if (d > max) return max;
    return d;
}

/* Function to get min value of a and b */
float min(float a, float b) {
  return a < b ? a : b;
}

/**
 * @brief Returns the average value of 100 readings at index + 3*n in the ADC_buffer vector.
 * It is assumed that ADC1_BUF contains data from 3 channels, collected sequentially.
 * For example, if index == 0, elements 0, 3, 6, ... are used;
 * if index == 1, then 1, 4, 7, ... and so on.
 * @param index Channel index (0, 1, or 2)
 * @return Average value for that channel
 */
float get_mean_ADC_reading_indexed(uint8_t index){
	if (index > 2) return 0.0f;  // Incorrect Index Protection

    float ADC_filter_mean = 0.0f;
    int count = 0;

    for (int n = index; n < ADC1_BUF_LEN; n += 3) {
        ADC_filter_mean += ADC1_BUF[n];
        count++;
    }

    return (count > 0) ? (ADC_filter_mean / (float)count) : 0.0f;
}

/**
 * @brief Retrieves the hardware version of the device based on the state of 3 input pins.
 * The states of the VERSION_BIT_1..3 pins form a 3-bit number:
 *     VERSION_BIT_3 - most significant bit (MSB)
 *     VERSION_BIT_2 - middle bit
 *     VERSION_BIT_1 - least significant bit (LSB)
 *
 * Version numbering starts from 3, i.e., version = 3 + [bit value]
 *
 * @return uint8_t Hardware version number (3..10)
 */
uint8_t get_hw_version(){
    uint8_t version_bits =
        (HAL_GPIO_ReadPin(GPIOC, VERSION_BIT_3_Pin) << 2) |
        (HAL_GPIO_ReadPin(GPIOC, VERSION_BIT_2_Pin) << 1) |
        (HAL_GPIO_ReadPin(GPIOC, VERSION_BIT_1_Pin) << 0);

    return 3 + version_bits;
}

/* Convert RGB colour to BRG color */
uint16_t RGB_to_BRG(uint16_t color){
	return ((((color & 0b0000000000011111)  << 11) & 0b1111100000000000) | ((color & 0b1111111111100000) >> 5));
}

/* Function to change the main state */
void change_state(mainstates new_state){
    // Save the previous state
	sensor_values.previous_state = sensor_values.current_state;
	// Set the new current state
	sensor_values.current_state = new_state;
    // If transitioning TO RUN STATE and the current temperature should be saved as the startup temperature
	if((sensor_values.previous_state != RUN) && (sensor_values.current_state == RUN) && (flash_values.startup_temp_is_previous_temp == 1)){
		flash_values.startup_temperature = sensor_values.set_temperature;
		FlashWrite(&flash_values);
	}
	// Enable GPIO4 when transitioning to RUN, if the corresponding setting is active
	if((sensor_values.current_state == RUN) && (flash_values.GPIO4_ON_at_run == 1)){
		HAL_GPIO_WritePin(GPIOB, USR_4_Pin, GPIO_PIN_SET); // Set the USR_4 output to high level
	}
	else{
		HAL_GPIO_WritePin(GPIOB, USR_4_Pin, GPIO_PIN_RESET); // Set the USR_4 output to low level
	}
    // Reset the beep flag upon reaching the temperature — only when entering RUN
    if((sensor_values.previous_state != RUN) && (sensor_values.current_state == RUN)){
            beeped_at_set_temp = 0;
    }
}

/* Function to get the filtered MCU temperature */
void get_mcu_temp(){
	sensor_values.mcu_temperature =	Moving_Average_Compute((((get_mean_ADC_reading_indexed(2) * VSENSE) - V30) / Avg_Slope + 25), &mcu_temperature_filter_struct); //Index 2 is MCU temp
}

/* Function to get the filtered bus voltage */
void get_bus_voltage(){
	sensor_values.bus_voltage = Moving_Average_Compute(get_mean_ADC_reading_indexed(0), &input_voltage_filterStruct)*VOLTAGE_COMPENSATION; //Index 0 is bus voltage
}

/* Function to get the filtered heater current */
void get_heater_current(){
	sensor_values.heater_current = Moving_Average_Compute(current_raw, &current_filterStruct)*CURRENT_COMPENSATION;
}

void get_thermocouple_temperature(){
	/* --- Step 1: Outlier filter on raw ADC data --- */
	TC_temp_from_ADC_previous = TC_temp_from_ADC;
	TC_temp_from_ADC = get_mean_ADC_reading_indexed(1);
	TC_temp_from_ADC_diff = fabs(TC_temp_from_ADC_previous - TC_temp_from_ADC);

	if((TC_temp_from_ADC_diff > TC_OUTLIERS_THRESHOLD) && (TC_outliers_detected < 2)){
		TC_outliers_detected++;
		if(TC_outliers_detected < 2){
			TC_temp_from_ADC = TC_temp_from_ADC_previous;
		}
	}
	else{
		TC_outliers_detected = 0;
	}

	/* --- Step 2: Moving average filter --- */
	TC_temp = Moving_Average_Compute(TC_temp_from_ADC, &thermocouple_temperature_filter_struct); /* Moving average */

	/* --- Step 3: Apply handle-specific compensation polynomial --- */
	if(attached_handle == T210){
		sensor_values.thermocouple_temperature = TC_temp*TC_temp*TC_COMPENSATION_X2_T210 + TC_temp*TC_COMPENSATION_X1_T210 + TC_COMPENSATION_X0_T210;
	}
	else if(attached_handle == T245){
		sensor_values.thermocouple_temperature = TC_temp*TC_temp*TC_COMPENSATION_X2_T245 + TC_temp*TC_COMPENSATION_X1_T245 + TC_COMPENSATION_X0_T245;
	}
	else if(attached_handle == NT115){
		sensor_values.thermocouple_temperature = TC_temp*TC_temp*TC_COMPENSATION_X2_NT115 + TC_temp*TC_COMPENSATION_X1_NT115 + TC_COMPENSATION_X0_NT115;
	}

	/* --- Step 4: Adjust measured temperature to fit calibrated values */
	if(sensor_values.thermocouple_temperature < 100){
		sensor_values.thermocouple_temperature = sensor_values.thermocouple_temperature*(flash_values.temp_cal_100)/100.0f;
		}
	else if(sensor_values.thermocouple_temperature < 200){
		sensor_values.thermocouple_temperature = (sensor_values.thermocouple_temperature - 100.0f)*(flash_values.temp_cal_200-flash_values.temp_cal_100)/100.0f + flash_values.temp_cal_100;
		}
	else if(sensor_values.thermocouple_temperature < 300){
		sensor_values.thermocouple_temperature = (sensor_values.thermocouple_temperature - 200.0f)*(flash_values.temp_cal_300-flash_values.temp_cal_200)/100.0f + flash_values.temp_cal_200;
	}
	else if(sensor_values.thermocouple_temperature < 350){
		sensor_values.thermocouple_temperature = (sensor_values.thermocouple_temperature - 300.0f)*(flash_values.temp_cal_350-flash_values.temp_cal_300)/50.0f + flash_values.temp_cal_300;
		}
	else if(sensor_values.thermocouple_temperature < 400){
		sensor_values.thermocouple_temperature = (sensor_values.thermocouple_temperature - 350.0f)*(flash_values.temp_cal_400-flash_values.temp_cal_350)/50.0f + flash_values.temp_cal_350;
		}
	else{
		sensor_values.thermocouple_temperature = (sensor_values.thermocouple_temperature - 400.0f)*(flash_values.temp_cal_450-flash_values.temp_cal_400)/50.0f + flash_values.temp_cal_400;
		}
	// Add temperature offset value
	sensor_values.thermocouple_temperature += flash_values.temperature_offset;
	// Clamp
	sensor_values.thermocouple_temperature = clamp(sensor_values.thermocouple_temperature ,0 ,500);

	sensor_values.thermocouple_temperature_filtered = Moving_Average_Compute(sensor_values.thermocouple_temperature, &thermocouple_temperature_filtered_filter_struct); // Moving average filter
	sensor_values.thermocouple_temperature_filtered = Hysteresis_Add(sensor_values.thermocouple_temperature_filtered, &thermocouple_temperature_filtered_hysteresis); // Hysteresis filter
}

/* Sets the duty cycle of timer controlling the heater */
void set_heater_duty(uint16_t dutycycle){
	__HAL_TIM_SET_COMPARE(&htim1, TIM_CHANNEL_3, dutycycle);
	__HAL_TIM_SET_COMPARE(&htim1, TIM_CHANNEL_1, (uint16_t)(dutycycle * 0.3f));
}

/* Update the duty cycle of timer controlling the heater PWM */
void update_heater_PWM(){
	if (sensor_values.bus_voltage <= 0.0f) return;

    float current = (sensor_values.max_power_watt * POWER_CONVERSION_FACTOR) / sensor_values.bus_voltage;
    float duty_cycle = sensor_values.requested_power * current;

    duty_cycle = clamp(duty_cycle, 0.0f, PID_MAX_OUTPUT);
    set_heater_duty(duty_cycle);
}

/* Disable the duty cycle of timer controlling the heater PWM*/
void heater_off(){
	set_heater_duty(0);
}

/* Return the temperature in the correct unit */
float convert_temperature(float temperature){
	if (flash_values.deg_celsius == 1){
		return temperature;
	}
	else{
		return ((temperature * 9) + 3) / 5 + 32;
	}
}

/* Formatting float into a string as right-aligned, by adding spaces on the left */
void format_number_right(float input, char* buffer) {
    int rounded = (int)roundf(input);
    clamp(rounded, 0, 999);

    char number_str[4]; // Enough for "100" + '\0'
    sprintf(number_str, "%d", rounded);

    int num_digits = strlen(number_str);
    int padding_spaces = (3 - num_digits) * 2;

    // Fill padding spaces first
    memset(buffer, ' ', padding_spaces);
    // Copy the number after the padding
    strcpy(buffer + padding_spaces, number_str);

    // Null terminate the full string
    buffer[padding_spaces + num_digits] = '\0';
}

/* Formatting float into a string as left-aligned, by adding spaces on the right */
void format_number_left(float input, char* buffer) {
    int rounded = (int)roundf(input);
    clamp(rounded, 0, 999);

    char number_str[4]; // "100" + '\0'
    sprintf(number_str, "%d", rounded);

    int num_digits = strlen(number_str);
    int padding_spaces = (3 - num_digits) * 2;

    // Copy number into buffer
    strcpy(buffer, number_str);

    // Add spaces to the right
    memset(buffer + num_digits, ' ', padding_spaces);
    buffer[num_digits + padding_spaces] = '\0';
}

void update_display(){
	float filtered_power_percent = sensor_values.requested_power_filtered/PID_MAX_OUTPUT;
	float filtered_power_watt = sensor_values.max_power_watt*filtered_power_percent;

	if((flash_values.screen_rotation == 0) || (flash_values.screen_rotation == 2)){
		memset(&DISPLAY_buffer, '\0', sizeof(DISPLAY_buffer));
		format_number_left(convert_temperature(sensor_values.set_temperature), DISPLAY_buffer);
		LCD_PutStr(19, 70, DISPLAY_buffer, FONT_arial_36X44_NUMBERS, RGB_to_BRG(C_WHITE), RGB_to_BRG(C_BLACK));

		if(cartridge_state == DETACHED) {
			LCD_PutStr(15, 160, " ---  ", FONT_arial_36X44_NUMBERS, RGB_to_BRG(C_WHITE), RGB_to_BRG(C_BLACK));
		}
		else{
			memset(&DISPLAY_buffer, '\0', sizeof(DISPLAY_buffer));
			format_number_left(convert_temperature(sensor_values.thermocouple_temperature_filtered), DISPLAY_buffer);
			LCD_PutStr(19, 160, DISPLAY_buffer, FONT_arial_36X44_NUMBERS, RGB_to_BRG(C_WHITE), RGB_to_BRG(C_BLACK));
		}

		memset(&DISPLAY_buffer, '\0', sizeof(DISPLAY_buffer));
		sprintf(DISPLAY_buffer, "%.1f", sensor_values.bus_voltage);
		LCD_PutStr(125, 255, DISPLAY_buffer, FONT_arial_17X18, RGB_to_BRG(C_WHITE), RGB_to_BRG(C_BLACK));

		memset(&DISPLAY_buffer, '\0', sizeof(DISPLAY_buffer));
		if(convert_temperature(sensor_values.mcu_temperature) < 99.5){
			sprintf(DISPLAY_buffer, "%.0f", convert_temperature(sensor_values.mcu_temperature));
		}
		else{
			sprintf(DISPLAY_buffer, "%.0f", convert_temperature(sensor_values.mcu_temperature));
		}
		LCD_PutStr(59, 275, DISPLAY_buffer, FONT_arial_17X18, RGB_to_BRG(C_WHITE), RGB_to_BRG(C_BLACK));

		if(attached_handle == T210){
			LCD_PutStr(125, 235, "T210   ", FONT_arial_17X18, RGB_to_BRG(C_WHITE), RGB_to_BRG(C_BLACK));
		}
		else if(attached_handle == T245){
			LCD_PutStr(125, 235, "T245   ", FONT_arial_17X18, RGB_to_BRG(C_WHITE), RGB_to_BRG(C_BLACK));
		}
		else if(attached_handle == NT115){
			LCD_PutStr(125, 235, "NT115", FONT_arial_17X18, RGB_to_BRG(C_WHITE), RGB_to_BRG(C_BLACK));
		}

		if(sensor_values.max_power_watt < 100){
			sprintf(DISPLAY_buffer, "  %.0f W", sensor_values.max_power_watt);
		}
		else{
			sprintf(DISPLAY_buffer, "%.0f W", sensor_values.max_power_watt);
		}
		LCD_PutStr(185, 45, DISPLAY_buffer, FONT_arial_17X18, RGB_to_BRG(C_WHITE), RGB_to_BRG(C_BLACK));

		memset(&DISPLAY_buffer, '\0', sizeof(DISPLAY_buffer));
		if(flash_values.power_unit == 0){
					format_number_right(filtered_power_watt, DISPLAY_buffer);
				}
				else{
					format_number_right(100*filtered_power_percent, DISPLAY_buffer);
				};
		LCD_PutStr(190, 275, DISPLAY_buffer, FONT_arial_17X18, RGB_to_BRG(C_WHITE), RGB_to_BRG(C_BLACK));

		if((sensor_values.current_state == SLEEP || sensor_values.current_state == EMERGENCY_SLEEP || sensor_values.current_state == HALTED) && !sleep_state_written_to_LCD){
			UG_FillFrame(210,66,230,268, RGB_to_BRG(C_ORANGE));
			LCD_PutStr(214, 73,  " ", FONT_arial_20X23, RGB_to_BRG(C_BLACK), RGB_to_BRG(C_ORANGE));
			LCD_PutStr(216, 99,  "S", FONT_arial_20X23, RGB_to_BRG(C_BLACK), RGB_to_BRG(C_ORANGE));
			LCD_PutStr(214, 129, "L", FONT_arial_20X23, RGB_to_BRG(C_BLACK), RGB_to_BRG(C_ORANGE));
			LCD_PutStr(216, 158, "E", FONT_arial_20X23, RGB_to_BRG(C_BLACK), RGB_to_BRG(C_ORANGE));
			LCD_PutStr(214, 191, "E", FONT_arial_20X23, RGB_to_BRG(C_BLACK), RGB_to_BRG(C_ORANGE));
			LCD_PutStr(216, 217, "P", FONT_arial_20X23, RGB_to_BRG(C_BLACK), RGB_to_BRG(C_ORANGE));
			LCD_PutStr(214, 247, " ", FONT_arial_20X23, RGB_to_BRG(C_BLACK), RGB_to_BRG(C_ORANGE));
			sleep_state_written_to_LCD = 1;
			standby_state_written_to_LCD = 0;
		}
		else if((sensor_values.current_state == STANDBY) && !standby_state_written_to_LCD){
			UG_FillFrame(210,66,230,268, RGB_to_BRG(C_ORANGE));
			LCD_PutStr(213, 73,  "S", FONT_arial_20X23, RGB_to_BRG(C_BLACK), RGB_to_BRG(C_ORANGE));
			LCD_PutStr(213, 102, "T", FONT_arial_20X23, RGB_to_BRG(C_BLACK), RGB_to_BRG(C_ORANGE));
			LCD_PutStr(213, 131, "A", FONT_arial_20X23, RGB_to_BRG(C_BLACK), RGB_to_BRG(C_ORANGE));
			LCD_PutStr(213, 160, "N", FONT_arial_20X23, RGB_to_BRG(C_BLACK), RGB_to_BRG(C_ORANGE));
			LCD_PutStr(213, 189, "D", FONT_arial_20X23, RGB_to_BRG(C_BLACK), RGB_to_BRG(C_ORANGE));
			LCD_PutStr(213, 218, "B", FONT_arial_20X23, RGB_to_BRG(C_BLACK), RGB_to_BRG(C_ORANGE));
			LCD_PutStr(213, 247, "Y", FONT_arial_20X23, RGB_to_BRG(C_BLACK), RGB_to_BRG(C_ORANGE));
			standby_state_written_to_LCD = 1;
			sleep_state_written_to_LCD = 0;
		}
		else if(sensor_values.current_state == RUN){
			UG_FillFrame(210, 268-filtered_power_percent*202, 	230, 	268,								RGB_to_BRG(C_LIGHT_SKY_BLUE));
			UG_FillFrame(210, 66, 								230, 	268-filtered_power_percent*202, 	RGB_to_BRG(C_BLACK));
			standby_state_written_to_LCD = 0;
			sleep_state_written_to_LCD = 0;
		}
	}
	else{
		memset(&DISPLAY_buffer, '\0', sizeof(DISPLAY_buffer));
		format_number_left(convert_temperature(sensor_values.set_temperature), DISPLAY_buffer);
		LCD_PutStr(64, 35, DISPLAY_buffer, FONT_arial_36X44_NUMBERS, RGB_to_BRG(C_WHITE), RGB_to_BRG(C_BLACK));

		if(cartridge_state == DETACHED) {
			LCD_PutStr(60, 115, " ---  ", FONT_arial_36X44_NUMBERS, RGB_to_BRG(C_WHITE), RGB_to_BRG(C_BLACK));
		}
		else{
			memset(&DISPLAY_buffer, '\0', sizeof(DISPLAY_buffer));
			format_number_left(convert_temperature(sensor_values.thermocouple_temperature_filtered), DISPLAY_buffer);
			LCD_PutStr(64, 115, DISPLAY_buffer, FONT_arial_36X44_NUMBERS, RGB_to_BRG(C_WHITE), RGB_to_BRG(C_BLACK));
		}

		memset(&DISPLAY_buffer, '\0', sizeof(DISPLAY_buffer));
		sprintf(DISPLAY_buffer, "%.1f", sensor_values.bus_voltage);
		LCD_PutStr(170, 195, DISPLAY_buffer, FONT_arial_17X18, RGB_to_BRG(C_WHITE), RGB_to_BRG(C_BLACK));

		memset(&DISPLAY_buffer, '\0', sizeof(DISPLAY_buffer));
		if(convert_temperature(sensor_values.mcu_temperature) < 99.5){
			sprintf(DISPLAY_buffer, "  %.0f", convert_temperature(sensor_values.mcu_temperature));
		}
		else{
			sprintf(DISPLAY_buffer, "%.0f", convert_temperature(sensor_values.mcu_temperature));
		}
		LCD_PutStr(102, 215, DISPLAY_buffer, FONT_arial_17X18, RGB_to_BRG(C_WHITE), RGB_to_BRG(C_BLACK));

		if(attached_handle == T210){
			LCD_PutStr(170, 175, "T210   ", FONT_arial_17X18, RGB_to_BRG(C_WHITE), RGB_to_BRG(C_BLACK));
		}
		else if(attached_handle == T245){
			LCD_PutStr(170, 175, "T245   ", FONT_arial_17X18, RGB_to_BRG(C_WHITE), RGB_to_BRG(C_BLACK));
		}
		else if(attached_handle == NT115){
			LCD_PutStr(170, 175, "NT115", FONT_arial_17X18, RGB_to_BRG(C_WHITE), RGB_to_BRG(C_BLACK));
		}

		if(sensor_values.max_power_watt < 100){
			sprintf(DISPLAY_buffer, "%.0f W  ", sensor_values.max_power_watt);
		}
		else{
			sprintf(DISPLAY_buffer, "%.0f W", sensor_values.max_power_watt);
		}
		LCD_PutStr(2, 10, DISPLAY_buffer, FONT_arial_17X18, RGB_to_BRG(C_WHITE), RGB_to_BRG(C_BLACK));

		memset(&DISPLAY_buffer, '\0', sizeof(DISPLAY_buffer));
		if(flash_values.power_unit == 0){ // power unit is set to W
					format_number_right(filtered_power_watt, DISPLAY_buffer);
				}
				else{
					format_number_right(100*filtered_power_percent, DISPLAY_buffer);
				};
		LCD_PutStr(5, 215, DISPLAY_buffer, FONT_arial_17X18, RGB_to_BRG(C_WHITE), RGB_to_BRG(C_BLACK));

		if((sensor_values.current_state == SLEEP || sensor_values.current_state == EMERGENCY_SLEEP || sensor_values.current_state == HALTED) && !sleep_state_written_to_LCD){
			UG_FillFrame(10,32,30,209, RGB_to_BRG(C_ORANGE));
			LCD_PutStr(14, 41,  "S", FONT_arial_20X23, RGB_to_BRG(C_BLACK), RGB_to_BRG(C_ORANGE));
			LCD_PutStr(16, 68,  "L", FONT_arial_20X23, RGB_to_BRG(C_BLACK), RGB_to_BRG(C_ORANGE));
			LCD_PutStr(14, 95,  "E", FONT_arial_20X23, RGB_to_BRG(C_BLACK), RGB_to_BRG(C_ORANGE));
			LCD_PutStr(16, 122, "E", FONT_arial_20X23, RGB_to_BRG(C_BLACK), RGB_to_BRG(C_ORANGE));
			LCD_PutStr(14, 149, "P", FONT_arial_20X23, RGB_to_BRG(C_BLACK), RGB_to_BRG(C_ORANGE));
			LCD_PutStr(16, 176, " ", FONT_arial_20X23, RGB_to_BRG(C_BLACK), RGB_to_BRG(C_ORANGE));
			sleep_state_written_to_LCD = 1;
			standby_state_written_to_LCD = 0;
		}
		else if((sensor_values.current_state == STANDBY) && !standby_state_written_to_LCD){
			UG_FillFrame(10,32,30,209, RGB_to_BRG(C_ORANGE));
			LCD_PutStr(14, 41,  "S", FONT_arial_20X23, RGB_to_BRG(C_BLACK), RGB_to_BRG(C_ORANGE));
			LCD_PutStr(14, 63,  "T", FONT_arial_20X23, RGB_to_BRG(C_BLACK), RGB_to_BRG(C_ORANGE));
			LCD_PutStr(14, 85,  "A", FONT_arial_20X23, RGB_to_BRG(C_BLACK), RGB_to_BRG(C_ORANGE));
			LCD_PutStr(14, 107, "N", FONT_arial_20X23, RGB_to_BRG(C_BLACK), RGB_to_BRG(C_ORANGE));
			LCD_PutStr(14, 129, "D", FONT_arial_20X23, RGB_to_BRG(C_BLACK), RGB_to_BRG(C_ORANGE));
			LCD_PutStr(14, 151, "B", FONT_arial_20X23, RGB_to_BRG(C_BLACK), RGB_to_BRG(C_ORANGE));
			LCD_PutStr(14, 173, "Y", FONT_arial_20X23, RGB_to_BRG(C_BLACK), RGB_to_BRG(C_ORANGE));
			standby_state_written_to_LCD = 1;
			sleep_state_written_to_LCD = 0;
		}
		else if(sensor_values.current_state == RUN){
			UG_FillFrame(10, 209-filtered_power_percent*177, 	30, 	209, 								RGB_to_BRG(C_LIGHT_SKY_BLUE));
			UG_FillFrame(10, 32, 								30, 	209-filtered_power_percent*177, 	RGB_to_BRG(C_BLACK));
			standby_state_written_to_LCD = 0;
			sleep_state_written_to_LCD = 0;
		}
	}
}

void LCD_draw_main_screen(){
	if((flash_values.screen_rotation == 0) || (flash_values.screen_rotation == 2)){
		UG_FillScreen(RGB_to_BRG(C_BLACK));

		LCD_PutStr(53, 8, "AxxSolder", FONT_arial_19X22, RGB_to_BRG(C_YELLOW), RGB_to_BRG(C_BLACK));
		LCD_DrawLine(0,36,240,36,RGB_to_BRG(C_YELLOW));
		LCD_DrawLine(0,37,240,37,RGB_to_BRG(C_YELLOW));
		LCD_DrawLine(0,38,240,38,RGB_to_BRG(C_YELLOW));

		LCD_PutStr(19, 45, "Set temp", FONT_arial_20X23, RGB_to_BRG(C_WHITE), RGB_to_BRG(C_BLACK));
		UG_DrawCircle(128, 76, 5, RGB_to_BRG(C_WHITE));
		UG_DrawCircle(128, 76, 4, RGB_to_BRG(C_WHITE));
		UG_DrawCircle(128, 76, 3, RGB_to_BRG(C_WHITE));
		if(flash_values.deg_celsius == 1){
			LCD_PutStr(135, 70, "C", FONT_arial_36X44_C, RGB_to_BRG(C_WHITE), RGB_to_BRG(C_BLACK));
		}
		else{
			LCD_PutStr(135, 70, "F", FONT_arial_36X44_F, RGB_to_BRG(C_WHITE), RGB_to_BRG(C_BLACK));
		}
		LCD_PutStr(19, 135, "Actual temp", FONT_arial_20X23, RGB_to_BRG(C_WHITE), RGB_to_BRG(C_BLACK));
		UG_DrawCircle(128, 166, 5, RGB_to_BRG(C_WHITE));
		UG_DrawCircle(128, 166, 4, RGB_to_BRG(C_WHITE));
		UG_DrawCircle(128, 166, 3, RGB_to_BRG(C_WHITE));
		if(flash_values.deg_celsius == 1){
			LCD_PutStr(135, 160, "C", FONT_arial_36X44_C, RGB_to_BRG(C_WHITE), RGB_to_BRG(C_BLACK));
		}
		else{
			LCD_PutStr(135, 160, "F", FONT_arial_36X44_F, RGB_to_BRG(C_WHITE), RGB_to_BRG(C_BLACK));
		}
		UG_DrawFrame(11, 129, 187, 215, RGB_to_BRG(C_WHITE));
		UG_DrawFrame(10, 128, 188, 216, RGB_to_BRG(C_WHITE));

		LCD_PutStr(11, 235, "Handle type:", FONT_arial_17X18, RGB_to_BRG(C_WHITE), RGB_to_BRG(C_BLACK));
		LCD_PutStr(11, 255, "Input voltage:         V", FONT_arial_17X18, RGB_to_BRG(C_WHITE), RGB_to_BRG(C_BLACK));
		if(flash_values.deg_celsius == 1){
			LCD_PutStr(11, 275, "MCU:     °C", FONT_arial_17X18, RGB_to_BRG(C_WHITE), RGB_to_BRG(C_BLACK));
		}
		else{
			LCD_PutStr(11, 275, "MCU:      °F", FONT_arial_17X18, RGB_to_BRG(C_WHITE), RGB_to_BRG(C_BLACK));
		}
		LCD_PutStr(108, 275, "SRC:", FONT_arial_17X18, RGB_to_BRG(C_WHITE), RGB_to_BRG(C_BLACK));
		switch(power_source){
		case POWER_DC:
			LCD_PutStr(154, 275, "DC", FONT_arial_17X18, RGB_to_BRG(C_WHITE), RGB_to_BRG(C_BLACK));
			break;
		case POWER_USB:
			LCD_PutStr(154, 275, "USB", FONT_arial_17X18, RGB_to_BRG(C_WHITE), RGB_to_BRG(C_BLACK));
			break;
		case POWER_BAT:
			LCD_PutStr(154, 275, "BAT", FONT_arial_17X18, RGB_to_BRG(C_WHITE), RGB_to_BRG(C_BLACK));
			break;
		}

		if(flash_values.power_unit == 0){ // power unit is set to W
			LCD_PutStr(223, 275, "W", FONT_arial_17X18, RGB_to_BRG(C_WHITE), RGB_to_BRG(C_BLACK));
		}
		else{
			LCD_PutStr(223, 275, "%", FONT_arial_17X18, RGB_to_BRG(C_WHITE), RGB_to_BRG(C_BLACK));
		};

		UG_DrawLine(0, 296, 240, 296, RGB_to_BRG(C_DARK_SEA_GREEN));
		UG_DrawLine(0, 297, 240, 297, RGB_to_BRG(C_DARK_SEA_GREEN));

		if(flash_values.three_button_mode == 1){
			LCD_PutStr(11, 301, "TEMP          UP   DOWN", FONT_arial_20X23, RGB_to_BRG(C_DARK_SEA_GREEN), RGB_to_BRG(C_BLACK));
		}
		else{
			LCD_PutStr(11, 301, "PRESETS", FONT_arial_20X23, RGB_to_BRG(C_DARK_SEA_GREEN), RGB_to_BRG(C_BLACK));
			memset(DISPLAY_buffer, '\0', sizeof(DISPLAY_buffer));
			sprintf(DISPLAY_buffer, "%.0f", convert_temperature(flash_values.preset_temp_1));
			LCD_PutStr(130, 301, DISPLAY_buffer, FONT_arial_20X23, RGB_to_BRG(C_DARK_SEA_GREEN), RGB_to_BRG(C_BLACK));
			memset(DISPLAY_buffer, '\0', sizeof(DISPLAY_buffer));
			sprintf(DISPLAY_buffer, "%.0f", convert_temperature(flash_values.preset_temp_2));
			LCD_PutStr(190, 301, DISPLAY_buffer, FONT_arial_20X23, RGB_to_BRG(C_DARK_SEA_GREEN), RGB_to_BRG(C_BLACK));
		}

		UG_DrawFrame(208, 64, 232, 270, RGB_to_BRG(C_WHITE));
		UG_DrawFrame(209, 65, 231, 269, RGB_to_BRG(C_WHITE));

	}
	else{
		UG_FillScreen(RGB_to_BRG(C_BLACK));
		LCD_PutStr(165, 10, "AxxSolder", FONT_arial_20X23, RGB_to_BRG(C_YELLOW), RGB_to_BRG(C_BLACK));

		LCD_PutStr(64, 10, "Set temp", FONT_arial_20X23, RGB_to_BRG(C_WHITE), RGB_to_BRG(C_BLACK));
		UG_DrawCircle(173, 41, 5, RGB_to_BRG(C_WHITE));
		UG_DrawCircle(173, 41, 4, RGB_to_BRG(C_WHITE));
		UG_DrawCircle(173, 41, 3, RGB_to_BRG(C_WHITE));
		if(flash_values.deg_celsius == 1){
			LCD_PutStr(180, 35, "C", FONT_arial_36X44_C, RGB_to_BRG(C_WHITE), RGB_to_BRG(C_BLACK));
		}
		else{
			LCD_PutStr(180, 35, "F", FONT_arial_36X44_F, RGB_to_BRG(C_WHITE), RGB_to_BRG(C_BLACK));
		}
		LCD_PutStr(64, 90, "Actual temp", FONT_arial_20X23, RGB_to_BRG(C_WHITE), RGB_to_BRG(C_BLACK));
		UG_DrawCircle(173, 121, 5, RGB_to_BRG(C_WHITE));
		UG_DrawCircle(173, 121, 4, RGB_to_BRG(C_WHITE));
		UG_DrawCircle(173, 121, 3, RGB_to_BRG(C_WHITE));
		if(flash_values.deg_celsius == 1){
			LCD_PutStr(180, 115, "C", FONT_arial_36X44_C, RGB_to_BRG(C_WHITE), RGB_to_BRG(C_BLACK));
		}
		else{
			LCD_PutStr(180, 115, "F", FONT_arial_36X44_F, RGB_to_BRG(C_WHITE), RGB_to_BRG(C_BLACK));
		}

		UG_DrawFrame(56, 84, 232,170, RGB_to_BRG(C_WHITE));
		UG_DrawFrame(56, 83, 233, 171, RGB_to_BRG(C_WHITE));

		LCD_PutStr(56, 175, "Handle type:", FONT_arial_17X18, RGB_to_BRG(C_WHITE), RGB_to_BRG(C_BLACK));
		LCD_PutStr(56, 195, "Input voltage:          V", FONT_arial_17X18, RGB_to_BRG(C_WHITE), RGB_to_BRG(C_BLACK));
		if(flash_values.deg_celsius == 1){
			LCD_PutStr(56, 215, "MCU:      °C", FONT_arial_17X18, RGB_to_BRG(C_WHITE), RGB_to_BRG(C_BLACK));
		}
		else{
			LCD_PutStr(56, 215, "MCU:       °F", FONT_arial_17X18, RGB_to_BRG(C_WHITE), RGB_to_BRG(C_BLACK));
		}
		LCD_PutStr(160, 215, "SRC:", FONT_arial_17X18, RGB_to_BRG(C_WHITE), RGB_to_BRG(C_BLACK));
		switch(power_source){
		case POWER_DC:
			LCD_PutStr(210, 215, "DC", FONT_arial_17X18, RGB_to_BRG(C_WHITE), RGB_to_BRG(C_BLACK));
			break;
		case POWER_USB:
			LCD_PutStr(210, 215, "USB", FONT_arial_17X18, RGB_to_BRG(C_WHITE), RGB_to_BRG(C_BLACK));
			break;
		case POWER_BAT:
			LCD_PutStr(210, 215, "BAT", FONT_arial_17X18, RGB_to_BRG(C_WHITE), RGB_to_BRG(C_BLACK));
			break;
		}

		UG_DrawLine(265, 0, 265, 240, RGB_to_BRG(C_DARK_SEA_GREEN));
		UG_DrawLine(266, 0, 266, 240, RGB_to_BRG(C_DARK_SEA_GREEN));
		UG_DrawLine(315, 0, 315, 240, RGB_to_BRG(C_DARK_SEA_GREEN));
		UG_DrawLine(316, 0, 316, 240, RGB_to_BRG(C_DARK_SEA_GREEN));

		if(flash_values.three_button_mode == 1){
			LCD_PutStr(269, 90, "INC", FONT_arial_20X23, RGB_to_BRG(C_DARK_SEA_GREEN), RGB_to_BRG(C_BLACK));
			LCD_PutStr(269, 10, "DEC", FONT_arial_20X23, RGB_to_BRG(C_DARK_SEA_GREEN), RGB_to_BRG(C_BLACK));
		}
		else{
			LCD_PutStr(285, 75, "P", FONT_arial_20X23, RGB_to_BRG(C_DARK_SEA_GREEN), RGB_to_BRG(C_BLACK));
			LCD_PutStr(285, 97, "R", FONT_arial_20X23, RGB_to_BRG(C_DARK_SEA_GREEN), RGB_to_BRG(C_BLACK));
			LCD_PutStr(285, 119, "E", FONT_arial_20X23, RGB_to_BRG(C_DARK_SEA_GREEN), RGB_to_BRG(C_BLACK));
			LCD_PutStr(285, 141, "S", FONT_arial_20X23, RGB_to_BRG(C_DARK_SEA_GREEN), RGB_to_BRG(C_BLACK));
			LCD_PutStr(285, 163, "E", FONT_arial_20X23, RGB_to_BRG(C_DARK_SEA_GREEN), RGB_to_BRG(C_BLACK));
			LCD_PutStr(285, 185, "T", FONT_arial_20X23, RGB_to_BRG(C_DARK_SEA_GREEN), RGB_to_BRG(C_BLACK));
			LCD_PutStr(285, 207, "S", FONT_arial_20X23, RGB_to_BRG(C_DARK_SEA_GREEN), RGB_to_BRG(C_BLACK));
			memset(&DISPLAY_buffer, '\0', sizeof(DISPLAY_buffer));
			sprintf(DISPLAY_buffer, "%.0f", flash_values.preset_temp_1);
			LCD_PutStr(272, 40, DISPLAY_buffer, FONT_arial_20X23, RGB_to_BRG(C_DARK_SEA_GREEN), RGB_to_BRG(C_BLACK));
			memset(&DISPLAY_buffer, '\0', sizeof(DISPLAY_buffer));
			sprintf(DISPLAY_buffer, "%.0f", flash_values.preset_temp_2);
			LCD_PutStr(272, 10, DISPLAY_buffer, FONT_arial_20X23, RGB_to_BRG(C_DARK_SEA_GREEN), RGB_to_BRG(C_BLACK));
		}

		UG_DrawFrame(8, 30, 32, 212, RGB_to_BRG(C_WHITE));
		UG_DrawFrame(9, 31, 31, 211, RGB_to_BRG(C_WHITE));

		if(flash_values.power_unit == 0){ // power unit is set to W
			LCD_PutStr(37, 215, "W", FONT_arial_17X18, RGB_to_BRG(C_WHITE), RGB_to_BRG(C_BLACK));
		}
		else{
			LCD_PutStr(37, 215, "%", FONT_arial_17X18, RGB_to_BRG(C_WHITE), RGB_to_BRG(C_BLACK));
		};

	}
}

void show_popup(char *text){
	UG_FillFrame(10, 50, 235, 105, RGB_to_BRG(C_ORANGE));
	UG_FillFrame(15, 55, 230, 100, RGB_to_BRG(C_WHITE));
	LCD_PutStr(20, 70, text, FONT_arial_20X23, RGB_to_BRG(C_ORANGE), RGB_to_BRG(C_WHITE));
	popup_shown = 1;
	previous_millis_popup = HAL_GetTick();
	standby_state_written_to_LCD = 0;
	sleep_state_written_to_LCD = 0;
}

void LCD_draw_earth_fault_popup(){
	heater_off();
	sensor_values.requested_power = 0.0f;

	UG_FillFrame(10, 50, 205, 205, RGB_to_BRG(C_ORANGE));
	UG_FillFrame(15, 55, 200, 200, RGB_to_BRG(C_WHITE));
	LCD_PutStr(20, 60, "GROUNDING", FONT_arial_20X23, RGB_to_BRG(C_ORANGE), RGB_to_BRG(C_WHITE));
	LCD_PutStr(20, 80, "ERROR", FONT_arial_20X23, RGB_to_BRG(C_ORANGE), RGB_to_BRG(C_WHITE));

	LCD_PutStr(20, 120, "CHECK", FONT_arial_20X23, RGB_to_BRG(C_ORANGE), RGB_to_BRG(C_WHITE));
	LCD_PutStr(20, 140, "CONNECTIONS", FONT_arial_20X23, RGB_to_BRG(C_ORANGE), RGB_to_BRG(C_WHITE));
	LCD_PutStr(20, 160, "AND REBOOT", FONT_arial_20X23, RGB_to_BRG(C_ORANGE), RGB_to_BRG(C_WHITE));

	Error_Handler();
}

/* Get encoder value (Set temp.) and limit */
void get_set_temperature(){
	if(custom_temperature_on == 0){
		uint16_t prev_temp = sensor_values.set_temperature;

		TIM2->CNT = clamp(TIM2->CNT, MIN_SELECTABLE_TEMPERATURE, MAX_SELECTABLE_TEMPERATURE);

		if(flash_values.three_button_mode == 1){
			sensor_values.set_temperature = (uint16_t)(TIM2->CNT);
		}
		else{
			sensor_values.set_temperature = (uint16_t)((TIM2->CNT) & ~1);
		}
		// Reset the flag if the set temperature has changed, so it beeps when reached
		if(sensor_values.set_temperature != prev_temp){
			beeped_at_set_temp = 0;  //
		}
	}
}

/* Function to check if the delta temperature is larger than expected */
void handle_delta_temperature(){
	if ((startup_done == 1) &&
		    ( (sensor_values.thermocouple_temperature - sensor_values.thermocouple_temperature_previous > MAX_TC_DELTA_FAULTDETECTION) ||
		      (sensor_values.thermocouple_temperature - sensor_values.thermocouple_temperature_previous < -MAX_TC_DELTA_FAULTDETECTION) )){
		//heater_off();
		sensor_values.requested_power = 0.0f;
		//sensor_values.heater_current = 0;
		change_state(EMERGENCY_SLEEP);
		//show_popup("No or Faulty tip!");
	}
	sensor_values.thermocouple_temperature_previous = sensor_values.thermocouple_temperature;
}

/* Function to set state to EMERGENCY_SLEEP */
void handle_emergency_shutdown(){
	/* Get time when iron turns on */
	if(sensor_values.previous_state != RUN && sensor_values.current_state == RUN){
		previous_millis_left_stand = HAL_GetTick();
	}
	/* Set state to EMERGENCY_SLEEP if iron ON for longer time than emergency_time */
	if ((sensor_values.in_stand == 0) && (HAL_GetTick() - previous_millis_left_stand >= flash_values.emergency_time*60000) && sensor_values.current_state == RUN){
		change_state(EMERGENCY_SLEEP);
		show_popup("Standby timeout");
	}
	/* Set state to EMERGENCY_SLEEP if input voltage is too low */
	if((sensor_values.bus_voltage <= MIN_BUSVOLTAGE) && (sensor_values.current_state == RUN)){
		change_state(EMERGENCY_SLEEP);
		show_popup("Inp. Voltage too low");
	}
	/* Set state to EMERGENCY_SLEEP if input power is too low */
	if((sensor_values.max_power_watt <= MIN_BUSPOWER) && (sensor_values.current_state == RUN)){
		change_state(EMERGENCY_SLEEP);
		show_popup("Inp. Power too low");
	}
	/* Set state to EMERGENCY_SLEEP if no tip detected (no current draw) */
	else if((sensor_values.heater_current < 1) && (sensor_values.current_state == RUN)){ //NT115 at 9V draws 2.3
		change_state(EMERGENCY_SLEEP);
		show_popup("No tip detected");
	}
	/* Set state to EMERGENCY_SLEEP if iron is over max allowed temp */
	else if((sensor_values.thermocouple_temperature_filtered > EMERGENCY_SHUTDOWN_TEMPERATURE) && (sensor_values.current_state == RUN)){
		change_state(EMERGENCY_SLEEP);
		show_popup("OVERTEMP");
	}
}

/* Function to handle the cartridge presence */
void handle_cartridge_presence(){
	if((sensor_values.heater_current < 1) || (TC_temp > 4096-10)) { //NT115 at 9V draws 2.3
		cartridge_state = DETACHED;
		change_state(EMERGENCY_SLEEP);
	}
	else{
		cartridge_state = ATTACHED;
	}
	/* When a inserted cartridge is detected - fill the moving average filter with TC measurements */
	if ((previous_cartridge_state == DETACHED) && (cartridge_state == ATTACHED)){
		HAL_Delay(100);
		Moving_Average_Set_Value(sensor_values.thermocouple_temperature, &thermocouple_temperature_filtered_filter_struct);
	}
	previous_cartridge_state = cartridge_state;
}

/* Function to toggle between RUN and HALTED at each press of the encoder button */
void handle_button_status(){
	if(SW_1_pressed == 1){
		SW_1_pressed = 0;
		// toggle between RUN and HALTED
		if ((sensor_values.current_state == RUN) || (sensor_values.current_state == STANDBY)){
			change_state(HALTED);
		}
		else if ((sensor_values.current_state == HALTED) || (sensor_values.current_state == EMERGENCY_SLEEP)){
			change_state(RUN);
		}
		previous_millis_heating_halted_update = HAL_GetTick();
	}
  if(SW_1_pressed_long == 1){
		SW_1_pressed_long = 0;
		/* start settings menu */
		settings_menu();
	}

	if(SW_1_pressed_long_long == 1){
		SW_1_pressed_long_long=0;
		// start power graph
		draw_pwr_graph=1;
		 //TODO:J.K:Add drawing power graph LONG LONG press SW1
	}

	/* Set "set temp" to preset temp 1 */
	if(SW_2_pressed == 1){
		SW_2_pressed = 0;
		if(settings_menu_active == 1){
			TIM2->CNT += 2;
		}
		else if(flash_values.three_button_mode == 1){
			TIM2->CNT += 5;
		}
		else{
			TIM2->CNT = flash_values.preset_temp_1;
		}
	}
	if(SW_2_pressed_long == 1){
		SW_2_pressed_long = 0;
		if(settings_menu_active == 0){
			if(flash_values.three_button_mode == 0){
				flash_values.preset_temp_1 = TIM2->CNT;
				FlashWrite(&flash_values);
				LCD_draw_main_screen();
				sleep_state_written_to_LCD = 0;
			}
		}
	}

	/* Set "set temp" to preset temp 2 */
	if(SW_3_pressed == 1){
		SW_3_pressed = 0;
		if(settings_menu_active == 1){
			TIM2->CNT -= 2;
		}
		else if(flash_values.three_button_mode == 1){
				TIM2->CNT -= 5;
			}
		else{
			TIM2->CNT = flash_values.preset_temp_2;
		}
	}
	if(SW_3_pressed_long == 1){
		SW_3_pressed_long = 0;
		if(settings_menu_active == 0){
			if(flash_values.three_button_mode == 0){
				flash_values.preset_temp_2 = TIM2->CNT;
				FlashWrite(&flash_values);
				LCD_draw_main_screen();
				sleep_state_written_to_LCD = 0;
			}
		}
	}
}

/* Get the status of handle in/on stand to trigger SLEEP */
void get_stand_status(){
	// Read stand input: low level = handle is in the stand
	uint8_t stand_status = 0;
	if(flash_values.detect_nt115 == 1){
		stand_status = (HAL_GPIO_ReadPin(GPIOA, STAND_INP_Pin) == GPIO_PIN_RESET) ? 1 : 0;
	}
	else{
		stand_status = ((HAL_GPIO_ReadPin(GPIOA, STAND_INP_Pin) == GPIO_PIN_RESET) || (HAL_GPIO_ReadPin (GPIOA, HANDLE_INP_2_Pin) == GPIO_PIN_RESET)) ? 1 : 0;
	};

	/* If the momentary stand function is not used */
	if(flash_values.momentary_stand == 0){
		sensor_values.in_stand = Moving_Average_Compute(stand_status, &stand_sense_filterStruct); // Moving average filter
	}
	/* If the momentary stand function is used, de-bounce the stand input */
	else{
		if(stand_status != previous_stand_status){ // If the stand status changed, due to noise or pressing:
			previous_stand_debounce = HAL_GetTick(); // reset the de-bouncing timer
			previous_stand_status = stand_status;
			stand_debounced_flag = 0;
		}

		else if(!stand_debounced_flag && (HAL_GetTick() - previous_stand_debounce) > interval_stand_debounce){
			stand_debounced_flag = 1;
			if(stand_status == 1){
				if(sensor_values.in_stand == 0){
					beep(flash_values.buzzer_enabled);
					sensor_values.in_stand = 1;
				}
				else{
					beep_double(flash_values.buzzer_enabled);
					sensor_values.in_stand = 0;
				}
			}
	    }
	}

	/* If handle is in stand set state to STANDBY */
	if(sensor_values.in_stand >= 0.2f){
		if (sensor_values.current_state == RUN){
			change_state(STANDBY);
			previous_millis_standby = HAL_GetTick();
		}
		if((HAL_GetTick()-previous_millis_standby >= flash_values.standby_time*60000.0) && (sensor_values.current_state == STANDBY)){
			change_state(SLEEP);
		}
		if ((sensor_values.current_state == EMERGENCY_SLEEP) || (sensor_values.current_state == HALTED)){
			change_state(SLEEP);
		}
	}

	/* If handle is NOT in stand and state is SLEEP, change state to RUN */
	if(sensor_values.in_stand < 0.2){
		if ((sensor_values.current_state == SLEEP) || (sensor_values.current_state == STANDBY) || (sensor_values.current_state == RUN)){
			change_state(RUN);
		}
	}
}

/* Automatically detect handle type, NT115, T210 or T245 based on HANDLE_INP_1_Pin and HANDLE_INP_2_Pin.*/
void get_handle_type(){
	uint8_t handle1_status = (HAL_GPIO_ReadPin (GPIOA, HANDLE_INP_1_Pin) == GPIO_PIN_RESET) ? 0 : 1;
	sensor_values.handle1_sense = Moving_Average_Compute(handle1_status, &handle1_sense_filterStruct); // Moving average filter

	uint8_t handle2_status = (HAL_GPIO_ReadPin (GPIOA, HANDLE_INP_2_Pin) == GPIO_PIN_RESET) ? 0 : 1;
	sensor_values.handle2_sense = Moving_Average_Compute(handle2_status, &handle2_sense_filterStruct); // Moving average filte

	/* Determine if NT115 handle is detected */
	if((sensor_values.handle1_sense >= 0.5f) && (sensor_values.handle2_sense < 0.5f) && (flash_values.detect_nt115 == 1)){
		attached_handle = NT115;
	}
	/* Determine if T210 handle is detected */
	else if((sensor_values.handle1_sense < 0.5f) && (sensor_values.handle2_sense >= 0.5f)){
		attached_handle = T210;
	}
	/* Determine if T245 handle is detected */
	else{
		attached_handle = T245;
	}
}

/* Function to set heating values depending on detected handle */
void set_handle_values(){
	uint16_t usb_limit = sensor_values.USB_PD_power_limit;

	switch (attached_handle) {
		case NT115:
			sensor_values.max_power_watt = min(usb_limit, NT115_MAX_POWER);
			PID_SetTunings(&TPID, KP_NT115, KI_NT115, KD_NT115);
			PID_SetILimits(&TPID, -MAX_I_NT115, MAX_I_NT115);
			break;

		case T210:
			sensor_values.max_power_watt = min(usb_limit, T210_MAX_POWER);
			PID_SetTunings(&TPID, KP_T210, KI_T210, KD_T210);
			PID_SetILimits(&TPID, -MAX_I_T210, MAX_I_T210);
			break;

		case T245:
			sensor_values.max_power_watt = min(usb_limit, T245_MAX_POWER);
			PID_SetTunings(&TPID, KP_T245, KI_T245, KD_T245);
			PID_SetILimits(&TPID, -MAX_I_T245, MAX_I_T245);
			break;

		case No_name:
			break;
	}

	// Override from flash if specified
    if (flash_values.power_limit != 0) {
        if(flash_values.power_limit < sensor_values.max_power_watt){
            sensor_values.max_power_watt = flash_values.power_limit;
        }
    }
}

/* Signal that the set temperature has been reached */
void beep_at_set_temp(){
    if (!flash_values.beep_at_set_temp) return;
    if (beeped_at_set_temp) return;

    float temp = sensor_values.thermocouple_temperature_filtered;
    float target = sensor_values.set_temperature;
    float delta = fabsf(temp - target);

    if (delta <= 5.0f){
		beeped_at_set_temp = 1;
		beep_double(flash_values.buzzer_enabled);
	}
}

/* Interrupts at button press */
volatile static uint16_t btnPressed = 0;
volatile static uint16_t debounceDone = 0;
void HAL_GPIO_EXTI_Callback(uint16_t GPIO_Pin)
{
    if(((GPIO_Pin == SW_1_Pin) || (GPIO_Pin == SW_2_Pin) || (GPIO_Pin == SW_3_Pin)) && (SW_ready == 1)){ //A button is pressed
    	btnPressed = GPIO_Pin;
		HAL_TIM_Base_Start_IT(&htim16);
		SW_ready = 0;
		debounceDone = 0;
    }
}

/* Interrupts at every encoder increment */
void HAL_TIM_IC_CaptureCallback(TIM_HandleTypeDef *htim){
	if ((htim->Channel == HAL_TIM_ACTIVE_CHANNEL_1) || (htim->Channel == HAL_TIM_ACTIVE_CHANNEL_2) ) {
		beep(flash_values.buzzer_enabled);
	}
}

/* Timer Callbacks */
void HAL_TIM_PWM_PulseFinishedCallback(TIM_HandleTypeDef *htim){
    if (htim->Instance == TIM1 && htim->Channel == HAL_TIM_ACTIVE_CHANNEL_1)
    {
        if (current_measurement_requested == 1 && current_measurement_done == 0)
        {
        	uint32_t duty_now = __HAL_TIM_GET_COMPARE(&htim1, TIM_CHANNEL_3);

        	if ( duty_now == FIXED_MEASURE_DUTY )
        	{   // check: is the level high on HEATER_Pin (CH3)
        		if ( (HAL_GPIO_ReadPin(HEATER_GPIO_Port, HEATER_Pin) == GPIO_PIN_SET) )
        		{
        			//HAL_GPIO_WritePin(USR_1_GPIO_Port, USR_1_Pin, GPIO_PIN_SET);
        			current_measurement_requested = 0;

        			HAL_ADC_Start_DMA(&hadc2, (uint32_t*)adc2_dma_buffer, 2);
        		}
        	}
        }
    }
}

void HAL_TIM_PeriodElapsedCallback(TIM_HandleTypeDef *htim){
	/* Take thermocouple measurement every 25 ms */
	if (htim == &htim6){
		thermocouple_measurement_done = 0;
		heater_off();
		__HAL_TIM_ENABLE(&htim7);
	}

	if (htim == &htim7){
		HAL_ADC_Start_DMA(&hadc1, (uint32_t*)ADC1_BUF, (uint32_t)ADC1_BUF_LEN);	//Start ADC DMA mode
		}

	/* Beep length timer */
	if (htim == &htim17){
		HAL_TIM_PWM_Stop_IT(&htim4, TIM_CHANNEL_2);
		HAL_TIM_Base_Stop_IT(&htim17);

	}

	/* Button De-bounce timer (50 ms) */
	static uint8_t timerCycles = 0;
	if(SW_ready == 0 && debounceDone == 0){
		timerCycles = 0;
		if((btnPressed == SW_1_Pin && HAL_GPIO_ReadPin(SW_1_GPIO_Port, SW_1_Pin) == GPIO_PIN_SET) ||
		   (btnPressed == SW_2_Pin && HAL_GPIO_ReadPin(SW_2_GPIO_Port, SW_2_Pin) == GPIO_PIN_SET) ||
	       (btnPressed == SW_3_Pin && HAL_GPIO_ReadPin(SW_3_GPIO_Port, SW_3_Pin) == GPIO_PIN_SET)){
			debounceDone = 1;
		}else{
			HAL_TIM_Base_Stop_IT(&htim16);
			SW_ready = 1;
		}
	}

	if (debounceDone == 1 && htim == &htim16 && SW_ready == 0){
		HAL_TIM_Base_Stop_IT(&htim16);
		if(btnPressed == SW_1_Pin && HAL_GPIO_ReadPin(SW_1_GPIO_Port, SW_1_Pin) == GPIO_PIN_RESET){
			SW_ready = 1;
			SW_1_pressed = 1;
			beep(flash_values.buzzer_enabled);
			timerCycles = 0;
		}else if(timerCycles > BTN_LONG_PRESS && timerCycles < BTN_LONG_LONG_PRESS && btnPressed == SW_1_Pin && HAL_GPIO_ReadPin(SW_1_GPIO_Port, SW_1_Pin) == GPIO_PIN_RESET){
			SW_ready = 1;
			beep(flash_values.buzzer_enabled);
			SW_1_pressed_long = 1;
			timerCycles = 0;
		}
		else if(timerCycles > BTN_LONG_LONG_PRESS && btnPressed == SW_1_Pin && HAL_GPIO_ReadPin(SW_1_GPIO_Port, SW_1_Pin) == GPIO_PIN_SET){
			SW_ready = 1;
			beep(flash_values.buzzer_enabled);
			SW_1_pressed_long_long = 1;
			timerCycles = 0;
			//TODO:J.K:Add handler to LONG LONG press of SW1
		}
		else if(btnPressed == SW_2_Pin && HAL_GPIO_ReadPin(SW_2_GPIO_Port, SW_2_Pin) == GPIO_PIN_RESET){
			SW_ready = 1;
			SW_2_pressed = 1;
			beep(flash_values.buzzer_enabled);
			timerCycles = 0;
		}else if(timerCycles > BTN_LONG_PRESS && btnPressed == SW_2_Pin && HAL_GPIO_ReadPin(SW_2_GPIO_Port, SW_2_Pin) == GPIO_PIN_SET){
			SW_ready = 1;
			beep(flash_values.buzzer_enabled);
			SW_2_pressed_long = 1;
			timerCycles = 0;
		}
		else if(btnPressed == SW_3_Pin && HAL_GPIO_ReadPin(SW_3_GPIO_Port, SW_3_Pin) == GPIO_PIN_RESET){
			SW_ready = 1;
			SW_3_pressed = 1;
			beep(flash_values.buzzer_enabled);
			timerCycles = 0;
		}
		else if(timerCycles > BTN_LONG_PRESS && btnPressed == SW_3_Pin && HAL_GPIO_ReadPin(SW_3_GPIO_Port, SW_3_Pin) == GPIO_PIN_SET){
			SW_ready = 1;
			beep(flash_values.buzzer_enabled);
			SW_3_pressed_long = 1;
			timerCycles = 0;
		}else{
			HAL_TIM_Base_Start_IT(&htim16);
			timerCycles++;
		}
	}
}
/* ADC conversion completed Callbacks */
void HAL_ADC_ConvCpltCallback(ADC_HandleTypeDef* hadc){
	if ((hadc->Instance == ADC1) && (thermocouple_measurement_done == 0)){
		//HAL_GPIO_WritePin(USR_1_GPIO_Port, USR_1_Pin, GPIO_PIN_SET);
		HAL_ADC_Stop_DMA(&hadc1);
		//HAL_GPIO_WritePin(USR_1_GPIO_Port, USR_1_Pin, GPIO_PIN_RESET);

		get_thermocouple_temperature();
		update_heater_PWM();
		thermocouple_measurement_done = 1;

		handle_delta_temperature();

	}
   	if ((hadc->Instance == ADC2) && (current_measurement_done == 0))
    {
        current_measurement_done = 1;

   		current_leak = adc2_dma_buffer[0];  // channel 2
        current_raw  = adc2_dma_buffer[1];  // channel 10

        sensor_values.leak_current = current_leak;

        update_heater_PWM();

    }
}

/* ADC watchdog Callback */
void HAL_ADC_LevelOutOfWindowCallback(ADC_HandleTypeDef* hadc __unused){
		LCD_draw_earth_fault_popup();
}

// For DEBUG
//HAL_GPIO_WritePin(USR_1_GPIO_Port, USR_1_Pin, GPIO_PIN_SET);
//HAL_GPIO_WritePin(GPIOB, USR_2_Pin, GPIO_PIN_RESET);
//HAL_GPIO_WritePin(GPIOB, USR_3_Pin, GPIO_PIN_RESET);
//HAL_GPIO_WritePin(GPIOB, USR_4_Pin, GPIO_PIN_RESET);

/* USER CODE END 0 */

int main(void)
{

  /* MCU Configuration--------------------------------------------------------*/

  /* Reset of all peripherals, Initializes the Flash interface and the Systick. */
  HAL_Init();

  /* Configure the system clock */
  SystemClock_Config();

  /* Initialize all configured peripherals */
  MX_GPIO_Init();
  MX_DMA_Init();
  MX_ADC1_Init();
  MX_ADC2_Init();
  MX_CRC_Init();
  MX_TIM1_Init();
  MX_TIM2_Init();
  MX_TIM4_Init();
  MX_SPI2_Init();
  MX_I2C1_Init();
  MX_USART1_UART_Init();
  MX_TIM7_Init();
  MX_TIM8_Init();
  MX_TIM6_Init();
  MX_TIM16_Init();
  MX_TIM17_Init();
  /* USER CODE BEGIN 2 */

	set_heater_duty(0);		//Set heater duty to zero to ensure zero startup current
	HAL_TIMEx_PWMN_Start_IT(&htim1, TIM_CHANNEL_3);

	HAL_TIM_Encoder_Start_IT(&htim2, TIM_CHANNEL_ALL);
	HAL_TIM_PWM_Start_IT(&htim1, TIM_CHANNEL_1);
	__HAL_TIM_SET_COMPARE(&htim4, TIM_CHANNEL_2, 50); //Set BUZZER duty to 50%
	HAL_TIM_Base_Start_IT(&htim6);

	__HAL_TIM_ENABLE_IT(&htim7, TIM_IT_UPDATE);

	HAL_ADCEx_Calibration_Start(&hadc2, ADC_SINGLE_ENDED);

	HAL_ADCEx_Calibration_Start(&hadc1, ADC_SINGLE_ENDED);
	HAL_ADC_Start_DMA(&hadc1, (uint32_t*)ADC1_BUF, (uint32_t)ADC1_BUF_LEN);	//Start ADC DMA mode

  /* USER CODE END 2 */

  /* Infinite loop */
  /* USER CODE BEGIN WHILE */
	HAL_Delay(200);

	// Check if user data in flash is valid, if not - write default parameters
	if(!FlashCheckCRC()){
		FlashWrite(&default_flash_values);
		beep(1); //Beep once to indicate default parameters written to flash
		HAL_Delay(100);
	}

	/* Read flash data */
	FlashRead(&flash_values);

	/* Initiate display */
	LCD_init();
	LCD_SetRotation(flash_values.screen_rotation);

	/* Set startup state */
	change_state(HALTED);

	/* Set initial encoder timer value */
	TIM2->CNT = flash_values.startup_temperature;

	/* initialize moving average functions */
	Moving_Average_Init(&thermocouple_temperature_filter_struct,(uint32_t)2);
	Moving_Average_Init(&thermocouple_temperature_filtered_filter_struct,(uint32_t)flash_values.displayed_temp_filter*10);
	Moving_Average_Init(&requested_power_filtered_filter_struct,(uint32_t)20);
	Moving_Average_Init(&mcu_temperature_filter_struct,(uint32_t)100);
	Moving_Average_Init(&input_voltage_filterStruct,(uint32_t)25);
	Moving_Average_Init(&current_filterStruct,(uint32_t)2);
	Moving_Average_Init(&stand_sense_filterStruct,(uint32_t)20);
	Moving_Average_Init(&handle1_sense_filterStruct,(uint32_t)20);
	Moving_Average_Init(&handle2_sense_filterStruct,(uint32_t)20);

	/* initialize hysteresis functions */
	Hysteresis_Init(&thermocouple_temperature_filtered_hysteresis, 0.5);

	/* Init and fill filter structures with initial values */
	for (int i = 0; i<200;i++){
		get_bus_voltage(); // Function to retrieve the filtered bus voltage
		get_heater_current(); // Function to retrieve the filtered heater current
		get_mcu_temp(); // Function to retrieve the MCU temperature
		get_thermocouple_temperature(); // Get thermocouple temperature
		get_handle_type(); // Get the handle type attached
		set_handle_values(); // Function to set heating values depending on the detected handle
		get_stand_status(); // Get handle stand status to activate SLEEP
		handle_button_status(); // Function to get button status
		handle_cartridge_presence(); // Function to monitor cartridge presence
	}

	/* Initiate PID controller */
	PID(&TPID, &sensor_values.thermocouple_temperature, &sensor_values.requested_power, &PID_setpoint, 0, 0, 0, _PID_CD_DIRECT); //PID parameters are set depending on detected handle by set_handle_values()
	PID_SetMode(&TPID, _PID_MODE_AUTOMATIC);
	PID_SetSampleTime(&TPID, PID_UPDATE_INTERVAL, 0); 		// Set PID update time to "PID_UPDATE_INTERVAL"
	PID_SetOutputLimits(&TPID, 0, PID_MAX_OUTPUT); 			// Set max and min output limit
	PID_SetILimits(&TPID, 0, 0);         					// Set max and min I limit
	PID_SetIminError(&TPID,PID_ADD_I_MIN_ERROR);			// Set I min Error
	PID_SetNegativeErrorIgainMult(&TPID, PID_NEG_ERROR_I_MULT, PID_NEG_ERROR_I_BIAS); // Set un-symmetric I gain parameters

	/* check STUSB4500 */
	HAL_StatusTypeDef halStatus;
	halStatus  = stusb_check_connection();
	if(halStatus != HAL_OK){
		//do error handling for STUSB
		debug_print_str(DEBUG_ERROR,"STUSB4500 unavailable");
	}else{
		debug_print_str(DEBUG_INFO,"STUSB4500 found");

		stusb_init();

		//1. check if cable is connected
		if(stusb_is_sink_connected()){

			//2. wait for sink to get ready
			while(!stusb_is_sink_ready()){
				debug_print_str(DEBUG_INFO,"Waiting for sink to get ready");
			}
			//if we are on USB-PD the sink needs some time to start
			HAL_Delay(500);

			stusb_soft_reset();

			//check if USB-PD is available
			STUSB_GEN1S_RDO_REG_STATUS_RegTypeDef rdo;
			halStatus = stusb_read_rdo(&rdo);
			volatile uint8_t currendPdoIndex = rdo.b.Object_Pos;
			if(currendPdoIndex == 0){
				debug_print_str(DEBUG_INFO,"No USB-PD detected");
			}else{
				power_source = POWER_USB;
				//The usb devices need some time to transmit the messages and execute the soft reset
				//HAL_Delay(4);
				//poll alert status since we don't have the alert interrupt pin connected
				//depending on the source we may need a few tries
				bool sourceStatus = false;
				for(int i=0;i<500;i++){
					sourceStatus = poll_source();
					if(sourceStatus){
						debug_print_str(DEBUG_INFO,"Got PDOs");
						uint8_t maxPowerAvailable = 0;
						stusb_set_highest_pdo(&maxPowerAvailable, currendPdoIndex);

						sensor_values.USB_PD_power_limit = maxPowerAvailable*USB_PD_POWER_REDUCTION_FACTOR;
						debug_print_int(DEBUG_INFO,"Reduced max power to", maxPowerAvailable*USB_PD_POWER_REDUCTION_FACTOR);
						//re-negotiate
						break;
					}
				}
			}
		}else{
			debug_print_str(DEBUG_INFO,"No USB-PD sink connected");
		}
	}

	/* Draw the main screen decoration */
	LCD_draw_main_screen();
	HAL_Delay(250);

	/* Set beep tone */
	switch((int)flash_values.beep_tone){
		case 0: {
			set_tone(1500, 10);
			break;
		}
		case 1: {
			set_tone(1500, 50);
			break;
		}
		case 2: {
			set_tone(800, 10);
			break;
		}
		case 3: {
			set_tone(800, 50);
			break;
		}
	}

    /* Start-up beep */
	beep_double(flash_values.startup_beep);

	//Flag to indicate that the startup sequence is done
	startup_done = 1;
	sensor_values.thermocouple_temperature_previous = sensor_values.thermocouple_temperature;

	/* Initiate the PID controller to zero*/
	//PID_Init_Zero();

	while (1){

		if(HAL_GetTick() - previous_sensor_update_high_update >= interval_sensor_update_high_update){
			get_stand_status();
			get_handle_type();
			set_handle_values();
			get_set_temperature();
			handle_button_status();
			handle_emergency_shutdown();
			handle_cartridge_presence();
			previous_sensor_update_high_update = HAL_GetTick();
		}

		if(HAL_GetTick() - previous_sensor_update_low_update >= interval_sensor_update_low_update){
			get_bus_voltage();
			get_heater_current();
			get_mcu_temp();
			beep_at_set_temp();
			previous_sensor_update_low_update = HAL_GetTick();
		}

		/* Compute PID */
		PID_Compute(&TPID);

		/* switch */
		switch(sensor_values.current_state) {
			case RUN: {
				PID_setpoint = sensor_values.set_temperature;
				break;
			}
			case STANDBY: {
			  if(flash_values.standby_temp > sensor_values.set_temperature){
				PID_setpoint = sensor_values.set_temperature;
			  }
			  else{
				PID_setpoint = flash_values.standby_temp;
			  }
			  break;
			}
			case SLEEP:
			case EMERGENCY_SLEEP:
			case HALTED: {
				PID_setpoint = 0;
				break;
			}
		}

		/* PID Tuning manual control */
		#ifdef PID_TUNING
		custom_temperature_on = 1;
		PID_SetTunings(&TPID, Kp_tuning, Ki_tuning, Kd_tuning/100.0);
		PID_SetILimits(&TPID, -PID_MAX_I_LIMIT_tuning, PID_MAX_I_LIMIT_tuning); 	// Set max and min I limit
		sensor_values.set_temperature = temperature_tuning;
		#endif

		/* Send debug information */
		if(flash_values.serial_debug_print == 1){
			if(HAL_GetTick() - previous_millis_debug >= interval_debug){
				UART_packet_length = 9*sizeof(float);
				pack_frame_start(UART_transmit_buffer, &UART_packet_index, UART_packet_length);
				pack_float(UART_transmit_buffer, &UART_packet_index, (float)sensor_values.thermocouple_temperature);
				pack_float(UART_transmit_buffer, &UART_packet_index, (float)sensor_values.thermocouple_temperature_filtered);
				pack_float(UART_transmit_buffer, &UART_packet_index, (float)PID_setpoint);
				pack_float(UART_transmit_buffer, &UART_packet_index, (float)sensor_values.requested_power/PID_MAX_OUTPUT*100.0f);
				pack_float(UART_transmit_buffer, &UART_packet_index, (float)sensor_values.requested_power_filtered/PID_MAX_OUTPUT*100.0f);
				pack_float(UART_transmit_buffer, &UART_packet_index, (float)PID_GetPpart(&TPID)/10.0f);
				pack_float(UART_transmit_buffer, &UART_packet_index, (float)PID_GetIpart(&TPID)/10.0f);
				pack_float(UART_transmit_buffer, &UART_packet_index, (float)PID_GetDpart(&TPID)/10.0f);
				pack_float(UART_transmit_buffer, &UART_packet_index, (float)sensor_values.heater_current);

				HAL_UART_Transmit_DMA(&huart1,(uint8_t*)UART_transmit_buffer, UART_packet_length+2); // Add two for starting bit and packet length
				previous_millis_debug = HAL_GetTick();
			}
		}

		/* Detect if a tip is present by sending a short voltage pulse and sense current */
		if (flash_values.current_measurement == 1){

			if (HAL_GetTick() - previous_measure_current_update >= interval_measure_current) {
				// Perform current measurement only if thermocouple measurement is not in progress.
				if (thermocouple_measurement_done == 1) {

					set_heater_duty(FIXED_MEASURE_DUTY);
					// Force the timer to update immediately so that the new value takes effect immediately
					htim1.Instance->EGR |= TIM_EGR_UG;  // Apply duty cycle immediately

					current_measurement_done = 0;
					current_measurement_requested = 1; // Measurement needs to be performed
					previous_measure_current_update = HAL_GetTick();
				}
			}
		}
		else{
			sensor_values.heater_current = 1; // If the current is not measured, apply a dummy value to heater_current
		}

		if(draw_pwr_graph==0){
			if(popup_shown == 1){
					if(HAL_GetTick() - previous_millis_popup >= interval_popup){
							popup_shown = 0;
							LCD_draw_main_screen(); // Clear the area where the emergency message is displayed
					}
			}
			else{
				/* Update display */
				if(HAL_GetTick() - previous_millis_display >= interval_display){
					sensor_values.requested_power_filtered = clamp(Moving_Average_Compute(sensor_values.requested_power, &requested_power_filtered_filter_struct), 0.0f, PID_MAX_OUTPUT);
					update_display();
					previous_millis_display = HAL_GetTick();
				}
			}
		}
		else{
        //TODO:JK Add handler to display power graph
        draw_graph_update();
		}

    /* USER CODE END WHILE */

  }
}

void SystemClock_Config(void)
{
  RCC_OscInitTypeDef RCC_OscInitStruct = {0};
  RCC_ClkInitTypeDef RCC_ClkInitStruct = {0};

  /** Configure the main internal regulator output voltage
  */
  HAL_PWREx_ControlVoltageScaling(PWR_REGULATOR_VOLTAGE_SCALE1_BOOST);

  /** Initializes the RCC Oscillators according to the specified parameters
  * in the RCC_OscInitTypeDef structure.
  */
  RCC_OscInitStruct.OscillatorType = RCC_OSCILLATORTYPE_HSI;
  RCC_OscInitStruct.HSIState = RCC_HSI_ON;
  RCC_OscInitStruct.HSICalibrationValue = RCC_HSICALIBRATION_DEFAULT;
  RCC_OscInitStruct.PLL.PLLState = RCC_PLL_ON;
  RCC_OscInitStruct.PLL.PLLSource = RCC_PLLSOURCE_HSI;
  RCC_OscInitStruct.PLL.PLLM = RCC_PLLM_DIV4;
  RCC_OscInitStruct.PLL.PLLN = 85;
  RCC_OscInitStruct.PLL.PLLP = RCC_PLLP_DIV2;
  RCC_OscInitStruct.PLL.PLLQ = RCC_PLLQ_DIV2;
  RCC_OscInitStruct.PLL.PLLR = RCC_PLLR_DIV2;
  if (HAL_RCC_OscConfig(&RCC_OscInitStruct) != HAL_OK)
  {
    Error_Handler();
  }

  /** Initializes the CPU, AHB and APB buses clocks
  */
  RCC_ClkInitStruct.ClockType = RCC_CLOCKTYPE_HCLK|RCC_CLOCKTYPE_SYSCLK
                              |RCC_CLOCKTYPE_PCLK1|RCC_CLOCKTYPE_PCLK2;
  RCC_ClkInitStruct.SYSCLKSource = RCC_SYSCLKSOURCE_PLLCLK;
  RCC_ClkInitStruct.AHBCLKDivider = RCC_SYSCLK_DIV1;
  RCC_ClkInitStruct.APB1CLKDivider = RCC_HCLK_DIV1;
  RCC_ClkInitStruct.APB2CLKDivider = RCC_HCLK_DIV1;

  if (HAL_RCC_ClockConfig(&RCC_ClkInitStruct, FLASH_LATENCY_4) != HAL_OK)
  {
    Error_Handler();
  }
}

static void MX_ADC1_Init(void)
{

  ADC_MultiModeTypeDef multimode = {0};
  ADC_ChannelConfTypeDef sConfig = {0};

  /** Common config
  */
  hadc1.Instance = ADC1;
  hadc1.Init.ClockPrescaler = ADC_CLOCK_ASYNC_DIV4;
  hadc1.Init.Resolution = ADC_RESOLUTION_12B;
  hadc1.Init.DataAlign = ADC_DATAALIGN_RIGHT;
  hadc1.Init.GainCompensation = 0;
  hadc1.Init.ScanConvMode = ADC_SCAN_ENABLE;
  hadc1.Init.EOCSelection = ADC_EOC_SINGLE_CONV;
  hadc1.Init.LowPowerAutoWait = DISABLE;
  hadc1.Init.ContinuousConvMode = ENABLE;
  hadc1.Init.NbrOfConversion = 3;
  hadc1.Init.DiscontinuousConvMode = DISABLE;
  hadc1.Init.ExternalTrigConv = ADC_SOFTWARE_START;
  hadc1.Init.ExternalTrigConvEdge = ADC_EXTERNALTRIGCONVEDGE_NONE;
  hadc1.Init.DMAContinuousRequests = ENABLE;
  hadc1.Init.Overrun = ADC_OVR_DATA_PRESERVED;
  hadc1.Init.OversamplingMode = DISABLE;
  if (HAL_ADC_Init(&hadc1) != HAL_OK)
  {
    Error_Handler();
  }

  /** Configure the ADC multi-mode
  */
  multimode.Mode = ADC_MODE_INDEPENDENT;
  if (HAL_ADCEx_MultiModeConfigChannel(&hadc1, &multimode) != HAL_OK)
  {
    Error_Handler();
  }

  /** Configure Regular Channel
  */
  sConfig.Channel = ADC_CHANNEL_3;
  sConfig.Rank = ADC_REGULAR_RANK_1;
  sConfig.SamplingTime = ADC_SAMPLETIME_247CYCLES_5;
  sConfig.SingleDiff = ADC_SINGLE_ENDED;
  sConfig.OffsetNumber = ADC_OFFSET_NONE;
  sConfig.Offset = 0;
  if (HAL_ADC_ConfigChannel(&hadc1, &sConfig) != HAL_OK)
  {
    Error_Handler();
  }

  /** Configure Regular Channel
  */
  sConfig.Channel = ADC_CHANNEL_4;
  sConfig.Rank = ADC_REGULAR_RANK_2;
  if (HAL_ADC_ConfigChannel(&hadc1, &sConfig) != HAL_OK)
  {
    Error_Handler();
  }

  /** Configure Regular Channel
  */
  sConfig.Channel = ADC_CHANNEL_TEMPSENSOR_ADC1;
  sConfig.Rank = ADC_REGULAR_RANK_3;
  if (HAL_ADC_ConfigChannel(&hadc1, &sConfig) != HAL_OK)
  {
    Error_Handler();
  }

}

static void MX_ADC2_Init(void)
{

  ADC_AnalogWDGConfTypeDef AnalogWDGConfig = {0};
  ADC_ChannelConfTypeDef sConfig = {0};

  /** Common config
  */
  hadc2.Instance = ADC2;
  hadc2.Init.ClockPrescaler = ADC_CLOCK_ASYNC_DIV4;
  hadc2.Init.Resolution = ADC_RESOLUTION_12B;
  hadc2.Init.DataAlign = ADC_DATAALIGN_RIGHT;
  hadc2.Init.GainCompensation = 0;
  hadc2.Init.ScanConvMode = ADC_SCAN_ENABLE;
  hadc2.Init.EOCSelection = ADC_EOC_SINGLE_CONV;
  hadc2.Init.LowPowerAutoWait = DISABLE;
  hadc2.Init.ContinuousConvMode = DISABLE;
  hadc2.Init.NbrOfConversion = 2;
  hadc2.Init.DiscontinuousConvMode = DISABLE;
  hadc2.Init.ExternalTrigConv = ADC_SOFTWARE_START;
  hadc2.Init.ExternalTrigConvEdge = ADC_EXTERNALTRIGCONVEDGE_NONE;
  hadc2.Init.DMAContinuousRequests = ENABLE;
  hadc2.Init.Overrun = ADC_OVR_DATA_PRESERVED;
  hadc2.Init.OversamplingMode = DISABLE;
  if (HAL_ADC_Init(&hadc2) != HAL_OK)
  {
    Error_Handler();
  }

  /** Configure Analog WatchDog 1
  */
  AnalogWDGConfig.WatchdogNumber = ADC_ANALOGWATCHDOG_1;
  AnalogWDGConfig.WatchdogMode = ADC_ANALOGWATCHDOG_SINGLE_REG;
  AnalogWDGConfig.Channel = ADC_CHANNEL_2;
  AnalogWDGConfig.ITMode = ENABLE;
  AnalogWDGConfig.HighThreshold = 2000;
  AnalogWDGConfig.LowThreshold = 0;
  AnalogWDGConfig.FilteringConfig = ADC_AWD_FILTERING_NONE;
  if (HAL_ADC_AnalogWDGConfig(&hadc2, &AnalogWDGConfig) != HAL_OK)
  {
    Error_Handler();
  }

  /** Configure Regular Channel
  */
  sConfig.Channel = ADC_CHANNEL_2;
  sConfig.Rank = ADC_REGULAR_RANK_1;
  sConfig.SamplingTime = ADC_SAMPLETIME_2CYCLES_5;
  sConfig.SingleDiff = ADC_SINGLE_ENDED;
  sConfig.OffsetNumber = ADC_OFFSET_NONE;
  sConfig.Offset = 0;
  if (HAL_ADC_ConfigChannel(&hadc2, &sConfig) != HAL_OK)
  {
    Error_Handler();
  }

  /** Configure Regular Channel
  */
  sConfig.Channel = ADC_CHANNEL_10;
  sConfig.Rank = ADC_REGULAR_RANK_2;
  if (HAL_ADC_ConfigChannel(&hadc2, &sConfig) != HAL_OK)
  {
    Error_Handler();
  }

}

static void MX_CRC_Init(void)
{

  hcrc.Instance = CRC;
  hcrc.Init.DefaultPolynomialUse = DEFAULT_POLYNOMIAL_ENABLE;
  hcrc.Init.DefaultInitValueUse = DEFAULT_INIT_VALUE_ENABLE;
  hcrc.Init.InputDataInversionMode = CRC_INPUTDATA_INVERSION_NONE;
  hcrc.Init.OutputDataInversionMode = CRC_OUTPUTDATA_INVERSION_DISABLE;
  hcrc.InputDataFormat = CRC_INPUTDATA_FORMAT_BYTES;
  if (HAL_CRC_Init(&hcrc) != HAL_OK)
  {
    Error_Handler();
  }

}

static void MX_I2C1_Init(void)
{

  hi2c1.Instance = I2C1;
  hi2c1.Init.Timing = 0x40B285C2;
  hi2c1.Init.OwnAddress1 = 0;
  hi2c1.Init.AddressingMode = I2C_ADDRESSINGMODE_7BIT;
  hi2c1.Init.DualAddressMode = I2C_DUALADDRESS_DISABLE;
  hi2c1.Init.OwnAddress2 = 0;
  hi2c1.Init.OwnAddress2Masks = I2C_OA2_NOMASK;
  hi2c1.Init.GeneralCallMode = I2C_GENERALCALL_DISABLE;
  hi2c1.Init.NoStretchMode = I2C_NOSTRETCH_DISABLE;
  if (HAL_I2C_Init(&hi2c1) != HAL_OK)
  {
    Error_Handler();
  }

  /** Configure Analogue filter
  */
  if (HAL_I2CEx_ConfigAnalogFilter(&hi2c1, I2C_ANALOGFILTER_ENABLE) != HAL_OK)
  {
    Error_Handler();
  }

  /** Configure Digital filter
  */
  if (HAL_I2CEx_ConfigDigitalFilter(&hi2c1, 0) != HAL_OK)
  {
    Error_Handler();
  }

}

static void MX_SPI2_Init(void)
{

  /* SPI2 parameter configuration*/
  hspi2.Instance = SPI2;
  hspi2.Init.Mode = SPI_MODE_MASTER;
  hspi2.Init.Direction = SPI_DIRECTION_1LINE;
  hspi2.Init.DataSize = SPI_DATASIZE_8BIT;
  hspi2.Init.CLKPolarity = SPI_POLARITY_LOW;
  hspi2.Init.CLKPhase = SPI_PHASE_1EDGE;
  hspi2.Init.NSS = SPI_NSS_SOFT;
  hspi2.Init.BaudRatePrescaler = SPI_BAUDRATEPRESCALER_8;
  hspi2.Init.FirstBit = SPI_FIRSTBIT_MSB;
  hspi2.Init.TIMode = SPI_TIMODE_DISABLE;
  hspi2.Init.CRCCalculation = SPI_CRCCALCULATION_DISABLE;
  hspi2.Init.CRCPolynomial = 7;
  hspi2.Init.CRCLength = SPI_CRC_LENGTH_DATASIZE;
  hspi2.Init.NSSPMode = SPI_NSS_PULSE_ENABLE;
  if (HAL_SPI_Init(&hspi2) != HAL_OK)
  {
    Error_Handler();
  }

}

static void MX_TIM1_Init(void)
{

  TIM_MasterConfigTypeDef sMasterConfig = {0};
  TIM_OC_InitTypeDef sConfigOC = {0};
  TIM_BreakDeadTimeConfigTypeDef sBreakDeadTimeConfig = {0};

  htim1.Instance = TIM1;
  htim1.Init.Prescaler = 17-1;
  htim1.Init.CounterMode = TIM_COUNTERMODE_UP;
  htim1.Init.Period = 500;
  htim1.Init.ClockDivision = TIM_CLOCKDIVISION_DIV1;
  htim1.Init.RepetitionCounter = 0;
  htim1.Init.AutoReloadPreload = TIM_AUTORELOAD_PRELOAD_ENABLE;
  if (HAL_TIM_PWM_Init(&htim1) != HAL_OK)
  {
    Error_Handler();
  }
  sMasterConfig.MasterOutputTrigger = TIM_TRGO_RESET;
  sMasterConfig.MasterOutputTrigger2 = TIM_TRGO2_RESET;
  sMasterConfig.MasterSlaveMode = TIM_MASTERSLAVEMODE_DISABLE;
  if (HAL_TIMEx_MasterConfigSynchronization(&htim1, &sMasterConfig) != HAL_OK)
  {
    Error_Handler();
  }
  sConfigOC.OCMode = TIM_OCMODE_PWM1;
  sConfigOC.Pulse = 0;
  sConfigOC.OCPolarity = TIM_OCPOLARITY_HIGH;
  sConfigOC.OCNPolarity = TIM_OCNPOLARITY_HIGH;
  sConfigOC.OCFastMode = TIM_OCFAST_DISABLE;
  sConfigOC.OCIdleState = TIM_OCIDLESTATE_RESET;
  sConfigOC.OCNIdleState = TIM_OCNIDLESTATE_RESET;
  if (HAL_TIM_PWM_ConfigChannel(&htim1, &sConfigOC, TIM_CHANNEL_1) != HAL_OK)
  {
    Error_Handler();
  }
  if (HAL_TIM_PWM_ConfigChannel(&htim1, &sConfigOC, TIM_CHANNEL_3) != HAL_OK)
  {
    Error_Handler();
  }
  sBreakDeadTimeConfig.OffStateRunMode = TIM_OSSR_DISABLE;
  sBreakDeadTimeConfig.OffStateIDLEMode = TIM_OSSI_DISABLE;
  sBreakDeadTimeConfig.LockLevel = TIM_LOCKLEVEL_OFF;
  sBreakDeadTimeConfig.DeadTime = 0;
  sBreakDeadTimeConfig.BreakState = TIM_BREAK_DISABLE;
  sBreakDeadTimeConfig.BreakPolarity = TIM_BREAKPOLARITY_HIGH;
  sBreakDeadTimeConfig.BreakFilter = 0;
  sBreakDeadTimeConfig.BreakAFMode = TIM_BREAK_AFMODE_INPUT;
  sBreakDeadTimeConfig.Break2State = TIM_BREAK2_DISABLE;
  sBreakDeadTimeConfig.Break2Polarity = TIM_BREAK2POLARITY_HIGH;
  sBreakDeadTimeConfig.Break2Filter = 0;
  sBreakDeadTimeConfig.Break2AFMode = TIM_BREAK_AFMODE_INPUT;
  sBreakDeadTimeConfig.AutomaticOutput = TIM_AUTOMATICOUTPUT_DISABLE;
  if (HAL_TIMEx_ConfigBreakDeadTime(&htim1, &sBreakDeadTimeConfig) != HAL_OK)
  {
    Error_Handler();
  }
  HAL_TIM_MspPostInit(&htim1);

}

static void MX_TIM2_Init(void)
{

  TIM_Encoder_InitTypeDef sConfig = {0};
  TIM_MasterConfigTypeDef sMasterConfig = {0};

  htim2.Instance = TIM2;
  htim2.Init.Prescaler = 0;
  htim2.Init.CounterMode = TIM_COUNTERMODE_UP;
  htim2.Init.Period = 4294967295;
  htim2.Init.ClockDivision = TIM_CLOCKDIVISION_DIV1;
  htim2.Init.AutoReloadPreload = TIM_AUTORELOAD_PRELOAD_DISABLE;
  sConfig.EncoderMode = TIM_ENCODERMODE_TI12;
  sConfig.IC1Polarity = TIM_ICPOLARITY_FALLING;
  sConfig.IC1Selection = TIM_ICSELECTION_DIRECTTI;
  sConfig.IC1Prescaler = TIM_ICPSC_DIV1;
  sConfig.IC1Filter = 0;
  sConfig.IC2Polarity = TIM_ICPOLARITY_RISING;
  sConfig.IC2Selection = TIM_ICSELECTION_DIRECTTI;
  sConfig.IC2Prescaler = TIM_ICPSC_DIV1;
  sConfig.IC2Filter = 0;
  if (HAL_TIM_Encoder_Init(&htim2, &sConfig) != HAL_OK)
  {
    Error_Handler();
  }
  sMasterConfig.MasterOutputTrigger = TIM_TRGO_RESET;
  sMasterConfig.MasterSlaveMode = TIM_MASTERSLAVEMODE_DISABLE;
  if (HAL_TIMEx_MasterConfigSynchronization(&htim2, &sMasterConfig) != HAL_OK)
  {
    Error_Handler();
  }

}

static void MX_TIM4_Init(void)
{

  TIM_MasterConfigTypeDef sMasterConfig = {0};
  TIM_OC_InitTypeDef sConfigOC = {0};

  htim4.Instance = TIM4;
  htim4.Init.Prescaler = 1700-1;
  htim4.Init.CounterMode = TIM_COUNTERMODE_UP;
  htim4.Init.Period = 100;
  htim4.Init.ClockDivision = TIM_CLOCKDIVISION_DIV1;
  htim4.Init.AutoReloadPreload = TIM_AUTORELOAD_PRELOAD_ENABLE;
  if (HAL_TIM_PWM_Init(&htim4) != HAL_OK)
  {
    Error_Handler();
  }
  sMasterConfig.MasterOutputTrigger = TIM_TRGO_RESET;
  sMasterConfig.MasterSlaveMode = TIM_MASTERSLAVEMODE_DISABLE;
  if (HAL_TIMEx_MasterConfigSynchronization(&htim4, &sMasterConfig) != HAL_OK)
  {
    Error_Handler();
  }
  sConfigOC.OCMode = TIM_OCMODE_PWM1;
  sConfigOC.Pulse = 0;
  sConfigOC.OCPolarity = TIM_OCPOLARITY_HIGH;
  sConfigOC.OCFastMode = TIM_OCFAST_DISABLE;
  if (HAL_TIM_PWM_ConfigChannel(&htim4, &sConfigOC, TIM_CHANNEL_2) != HAL_OK)
  {
    Error_Handler();
  }
  HAL_TIM_MspPostInit(&htim4);

}

static void MX_TIM6_Init(void)
{

  TIM_MasterConfigTypeDef sMasterConfig = {0};

  htim6.Instance = TIM6;
  htim6.Init.Prescaler = 17000-1;
  htim6.Init.CounterMode = TIM_COUNTERMODE_UP;
  htim6.Init.Period = 250;
  htim6.Init.AutoReloadPreload = TIM_AUTORELOAD_PRELOAD_ENABLE;
  if (HAL_TIM_Base_Init(&htim6) != HAL_OK)
  {
    Error_Handler();
  }
  sMasterConfig.MasterOutputTrigger = TIM_TRGO_RESET;
  sMasterConfig.MasterSlaveMode = TIM_MASTERSLAVEMODE_DISABLE;
  if (HAL_TIMEx_MasterConfigSynchronization(&htim6, &sMasterConfig) != HAL_OK)
  {
    Error_Handler();
  }

}

static void MX_TIM7_Init(void)
{

  TIM_MasterConfigTypeDef sMasterConfig = {0};

  htim7.Instance = TIM7;
  htim7.Init.Prescaler = 8500-1;
  htim7.Init.CounterMode = TIM_COUNTERMODE_UP;
  htim7.Init.Period = 9;
  htim7.Init.AutoReloadPreload = TIM_AUTORELOAD_PRELOAD_ENABLE;
  if (HAL_TIM_Base_Init(&htim7) != HAL_OK)
  {
    Error_Handler();
  }
  if (HAL_TIM_OnePulse_Init(&htim7, TIM_OPMODE_SINGLE) != HAL_OK)
  {
    Error_Handler();
  }
  sMasterConfig.MasterOutputTrigger = TIM_TRGO_UPDATE;
  sMasterConfig.MasterSlaveMode = TIM_MASTERSLAVEMODE_DISABLE;
  if (HAL_TIMEx_MasterConfigSynchronization(&htim7, &sMasterConfig) != HAL_OK)
  {
    Error_Handler();
  }

}

static void MX_TIM8_Init(void)
{

  TIM_MasterConfigTypeDef sMasterConfig = {0};

  htim8.Instance = TIM8;
  htim8.Init.Prescaler = 0;
  htim8.Init.CounterMode = TIM_COUNTERMODE_UP;
  htim8.Init.Period = 65535;
  htim8.Init.ClockDivision = TIM_CLOCKDIVISION_DIV1;
  htim8.Init.RepetitionCounter = 0;
  htim8.Init.AutoReloadPreload = TIM_AUTORELOAD_PRELOAD_DISABLE;
  if (HAL_TIM_OnePulse_Init(&htim8, TIM_OPMODE_SINGLE) != HAL_OK)
  {
    Error_Handler();
  }
  sMasterConfig.MasterOutputTrigger = TIM_TRGO_RESET;
  sMasterConfig.MasterOutputTrigger2 = TIM_TRGO2_RESET;
  sMasterConfig.MasterSlaveMode = TIM_MASTERSLAVEMODE_DISABLE;
  if (HAL_TIMEx_MasterConfigSynchronization(&htim8, &sMasterConfig) != HAL_OK)
  {
    Error_Handler();
  }

}

static void MX_TIM16_Init(void)
{

  htim16.Instance = TIM16;
  htim16.Init.Prescaler = 17000-1;
  htim16.Init.CounterMode = TIM_COUNTERMODE_UP;
  htim16.Init.Period = 499;
  htim16.Init.ClockDivision = TIM_CLOCKDIVISION_DIV1;
  htim16.Init.RepetitionCounter = 0;
  htim16.Init.AutoReloadPreload = TIM_AUTORELOAD_PRELOAD_ENABLE;
  if (HAL_TIM_Base_Init(&htim16) != HAL_OK)
  {
    Error_Handler();
  }

}

static void MX_TIM17_Init(void)
{

  htim17.Instance = TIM17;
  htim17.Init.Prescaler = 17000;
  htim17.Init.CounterMode = TIM_COUNTERMODE_UP;
  htim17.Init.Period = 49;
  htim17.Init.ClockDivision = TIM_CLOCKDIVISION_DIV1;
  htim17.Init.RepetitionCounter = 0;
  htim17.Init.AutoReloadPreload = TIM_AUTORELOAD_PRELOAD_ENABLE;
  if (HAL_TIM_Base_Init(&htim17) != HAL_OK)
  {
    Error_Handler();
  }
  if (HAL_TIM_OnePulse_Init(&htim17, TIM_OPMODE_SINGLE) != HAL_OK)
  {
    Error_Handler();
  }

}

static void MX_USART1_UART_Init(void)
{

  huart1.Instance = USART1;
  huart1.Init.BaudRate = 256000;
  huart1.Init.WordLength = UART_WORDLENGTH_8B;
  huart1.Init.StopBits = UART_STOPBITS_1;
  huart1.Init.Parity = UART_PARITY_NONE;
  huart1.Init.Mode = UART_MODE_TX_RX;
  huart1.Init.HwFlowCtl = UART_HWCONTROL_NONE;
  huart1.Init.OverSampling = UART_OVERSAMPLING_16;
  huart1.Init.OneBitSampling = UART_ONE_BIT_SAMPLE_DISABLE;
  huart1.Init.ClockPrescaler = UART_PRESCALER_DIV1;
  huart1.AdvancedInit.AdvFeatureInit = UART_ADVFEATURE_NO_INIT;
  if (HAL_UART_Init(&huart1) != HAL_OK)
  {
    Error_Handler();
  }
  if (HAL_UARTEx_SetTxFifoThreshold(&huart1, UART_TXFIFO_THRESHOLD_1_8) != HAL_OK)
  {
    Error_Handler();
  }
  if (HAL_UARTEx_SetRxFifoThreshold(&huart1, UART_RXFIFO_THRESHOLD_1_8) != HAL_OK)
  {
    Error_Handler();
  }
  if (HAL_UARTEx_DisableFifoMode(&huart1) != HAL_OK)
  {
    Error_Handler();
  }

}

static void MX_DMA_Init(void)
{

  /* DMA controller clock enable */
  __HAL_RCC_DMAMUX1_CLK_ENABLE();
  __HAL_RCC_DMA1_CLK_ENABLE();

  /* DMA interrupt init */
  /* DMA1_Channel1_IRQn interrupt configuration */
  HAL_NVIC_SetPriority(DMA1_Channel1_IRQn, 0, 0);
  HAL_NVIC_EnableIRQ(DMA1_Channel1_IRQn);
  /* DMA1_Channel2_IRQn interrupt configuration */
  HAL_NVIC_SetPriority(DMA1_Channel2_IRQn, 0, 0);
  HAL_NVIC_EnableIRQ(DMA1_Channel2_IRQn);
  /* DMA1_Channel3_IRQn interrupt configuration */
  HAL_NVIC_SetPriority(DMA1_Channel3_IRQn, 0, 0);
  HAL_NVIC_EnableIRQ(DMA1_Channel3_IRQn);
  /* DMA1_Channel4_IRQn interrupt configuration */
  HAL_NVIC_SetPriority(DMA1_Channel4_IRQn, 0, 0);
  HAL_NVIC_EnableIRQ(DMA1_Channel4_IRQn);

}

static void MX_GPIO_Init(void)
{
  GPIO_InitTypeDef GPIO_InitStruct = {0};

  /* GPIO Ports Clock Enable */
  __HAL_RCC_GPIOC_CLK_ENABLE();
  __HAL_RCC_GPIOF_CLK_ENABLE();
  __HAL_RCC_GPIOA_CLK_ENABLE();
  __HAL_RCC_GPIOB_CLK_ENABLE();

  /*Configure GPIO pin Output Level */
  HAL_GPIO_WritePin(GPIOB, USR_2_Pin|USR_3_Pin|USR_4_Pin|SPI2_SD_CS_Pin
                          |SPI2_CS_Pin|SPI2_DC_Pin|SPI2_RST_Pin, GPIO_PIN_RESET);

  /*Configure GPIO pin Output Level */
  HAL_GPIO_WritePin(USR_1_GPIO_Port, USR_1_Pin, GPIO_PIN_RESET);

  /*Configure GPIO pins : VERSION_BIT_1_Pin VERSION_BIT_2_Pin VERSION_BIT_3_Pin */
  GPIO_InitStruct.Pin = VERSION_BIT_1_Pin|VERSION_BIT_2_Pin|VERSION_BIT_3_Pin;
  GPIO_InitStruct.Mode = GPIO_MODE_INPUT;
  GPIO_InitStruct.Pull = GPIO_NOPULL;
  HAL_GPIO_Init(GPIOC, &GPIO_InitStruct);

  /*Configure GPIO pins : HANDLE_INP_1_Pin HANDLE_INP_2_Pin STAND_INP_Pin */
  GPIO_InitStruct.Pin = HANDLE_INP_1_Pin|HANDLE_INP_2_Pin|STAND_INP_Pin;
  GPIO_InitStruct.Mode = GPIO_MODE_INPUT;
  GPIO_InitStruct.Pull = GPIO_NOPULL;
  HAL_GPIO_Init(GPIOA, &GPIO_InitStruct);

  /*Configure GPIO pin : SW_2_Pin */
  GPIO_InitStruct.Pin = SW_2_Pin;
  GPIO_InitStruct.Mode = GPIO_MODE_IT_RISING;
  GPIO_InitStruct.Pull = GPIO_NOPULL;
  HAL_GPIO_Init(SW_2_GPIO_Port, &GPIO_InitStruct);

  /*Configure GPIO pins : USR_2_Pin USR_3_Pin USR_4_Pin SPI2_SD_CS_Pin
                           SPI2_CS_Pin SPI2_DC_Pin SPI2_RST_Pin */
  GPIO_InitStruct.Pin = USR_2_Pin|USR_3_Pin|USR_4_Pin|SPI2_SD_CS_Pin
                          |SPI2_CS_Pin|SPI2_DC_Pin|SPI2_RST_Pin;
  GPIO_InitStruct.Mode = GPIO_MODE_OUTPUT_PP;
  GPIO_InitStruct.Pull = GPIO_NOPULL;
  GPIO_InitStruct.Speed = GPIO_SPEED_FREQ_LOW;
  HAL_GPIO_Init(GPIOB, &GPIO_InitStruct);

  /*Configure GPIO pin : USR_1_Pin */
  GPIO_InitStruct.Pin = USR_1_Pin;
  GPIO_InitStruct.Mode = GPIO_MODE_OUTPUT_PP;
  GPIO_InitStruct.Pull = GPIO_NOPULL;
  GPIO_InitStruct.Speed = GPIO_SPEED_FREQ_LOW;
  HAL_GPIO_Init(USR_1_GPIO_Port, &GPIO_InitStruct);

  /*Configure GPIO pins : SW_1_Pin SW_3_Pin */
  GPIO_InitStruct.Pin = SW_1_Pin|SW_3_Pin;
  GPIO_InitStruct.Mode = GPIO_MODE_IT_RISING;
  GPIO_InitStruct.Pull = GPIO_NOPULL;
  HAL_GPIO_Init(GPIOB, &GPIO_InitStruct);

  /* EXTI interrupt init*/
  HAL_NVIC_SetPriority(EXTI9_5_IRQn, 0, 0);
  HAL_NVIC_EnableIRQ(EXTI9_5_IRQn);

}

void Error_Handler(void)
{
  /* USER CODE BEGIN Error_Handler_Debug */
  /* User can add his own implementation to report the HAL error return state */

	// Stop the heater PWM and reconfigure as a GPIO and set to RESET
	heater_off();
	HAL_TIMEx_PWMN_Stop_IT(&htim1, TIM_CHANNEL_3);

	GPIO_InitTypeDef GPIO_InitStruct = {0};

	/*Configure GPIO pin : CURRENT_Pin */
	GPIO_InitStruct.Pin = HEATER_Pin;
	GPIO_InitStruct.Mode = GPIO_MODE_OUTPUT_PP;
	GPIO_InitStruct.Pull = GPIO_NOPULL;
	GPIO_InitStruct.Speed = GPIO_SPEED_FREQ_LOW;
	HAL_GPIO_Init(GPIOF, &GPIO_InitStruct);
	HAL_GPIO_WritePin(GPIOF, HEATER_Pin, GPIO_PIN_RESET);

	__disable_irq();
  while (1)
  {
  }
  /* USER CODE END Error_Handler_Debug */
}
